VERSION ""

NS_ :

BS_:

BU_:

BO_ 2566786558 WSMSTR: 8 Vector__XXX
 SG_ NumberOfMembers : 0|8@1+ (1,0) [0|0] "" Vector__XXX

BO_ 2566838526 CA: 9 Vector__XXX
 SG_ ReservedBit : 48|1@1+ (1,0) [0|0] "" Vector__XXX
 SG_ AddressAssignment : 64|8@1+ (1,0) [0|255] "" Vector__XXX
 SG_ ArbitraryAddressCapable : 63|1@1+ (1,0) [0|1] "" Vector__XXX
 SG_ IndustryGroup M : 60|3@1+ (1,0) [0|7] "" Vector__XXX
 SG_ VehicleSystemInstance : 56|4@1+ (1,0) [0|15] "" Vector__XXX
 SG_ Function : 40|8@1+ (1,0) [0|255] "" Vector__XXX
 SG_ VehicleSystem m0 : 49|7@1+ (1,0) [0|127] "" Vector__XXX
 SG_ FunctionInstance : 35|5@1+ (1,0) [0|31] "" Vector__XXX
 SG_ ECUInstance : 32|3@1+ (1,0) [0|7] "" Vector__XXX
 SG_ ManufacturerCode : 21|11@1+ (1,0) [0|2047] "" Vector__XXX
 SG_ IdentityNumber : 0|21@1+ (1,0) [0|2097152] "" Vector__XXX
 SG_ VehicleSystem5 m5 : 49|7@1+ (1,0) [0|127] "" Vector__XXX
 SG_ VehicleSystem4 m4 : 49|7@1+ (1,0) [0|127] "" Vector__XXX
 SG_ VehicleSystem3 m3 : 49|7@1+ (1,0) [0|127] "" Vector__XXX
 SG_ VehicleSystem2 m2 : 49|7@1+ (1,0) [0|127] "" Vector__XXX
 SG_ VehicleSystem1 m1 : 49|7@1+ (1,0) [0|127] "" Vector__XXX

BO_ 2565799678 AC: 8 Vector__XXX
 SG_ ReservedBit : 48|1@1+ (1,0) [0|0] "" Vector__XXX
 SG_ ArbitraryAddressCapable : 63|1@1+ (1,0) [0|1] "" Vector__XXX
 SG_ IndustryGroup M : 60|3@1+ (1,0) [0|7] "" Vector__XXX
 SG_ VehicleSystemInstance : 56|4@1+ (1,0) [0|15] "" Vector__XXX
 SG_ Function : 40|8@1+ (1,0) [0|255] "" Vector__XXX
 SG_ FunctionInstance : 35|5@1+ (1,0) [0|31] "" Vector__XXX
 SG_ ECUInstance : 32|3@1+ (1,0) [0|7] "" Vector__XXX
 SG_ ManufacturerCode : 21|11@1+ (1,0) [0|2047] "" Vector__XXX
 SG_ IdentityNumber : 0|21@1+ (1,0) [0|2097152] "" Vector__XXX
 SG_ VehicleSystem m0 : 49|7@1+ (1,0) [0|127] "" Vector__XXX
 SG_ VehicleSystem5 m5 : 49|7@1+ (1,0) [0|127] "" Vector__XXX
 SG_ VehicleSystem4 m4 : 49|7@1+ (1,0) [0|127] "" Vector__XXX
 SG_ VehicleSystem3 m3 : 49|7@1+ (1,0) [0|127] "" Vector__XXX
 SG_ VehicleSystem2 m2 : 49|7@1+ (1,0) [0|127] "" Vector__XXX
 SG_ VehicleSystem1 m1 : 49|7@1+ (1,0) [0|127] "" Vector__XXX

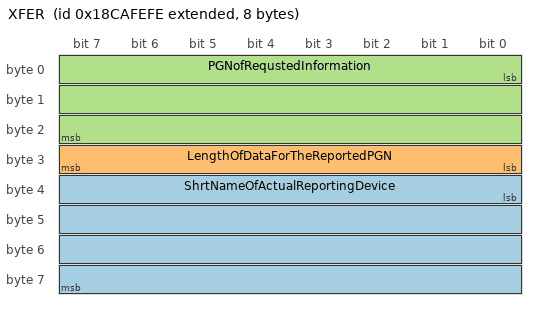
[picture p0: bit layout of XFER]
BO_ 2563440382 XFER: 8 Vector__XXX
 SG_ ShrtNameOfActualReportingDevice : 32|32@1+ (1,0) [0|0] "" Vector__XXX
 SG_ LengthOfDataForTheReportedPGN : 24|8@1+ (1,0) [0|255] "" Vector__XXX
 SG_ PGNofRequstedInformation : 0|24@1+ (1,0) [0|16777215] "" Vector__XXX

BO_ 2565603070 TPDT: 8 Vector__XXX
 SG_ SequenceNumber : 0|8@1+ (1,0) [0|255] "" Vector__XXX

BO_ 2565668606 TPCM: 8 Vector__XXX
 SG_ RoleOfSender m255 : 16|2@1+ (1,0) [0|0] "" Vector__XXX
 SG_ TotalNumberOfPacketsEoMA m19 : 24|8@1+ (1,0) [0|255] "" Vector__XXX
 SG_ TotalMessageSizeEoMA m19 : 8|16@1+ (1,0) [0|64255] "" Vector__XXX
 SG_ TotalMessageSizeBAM m32 : 8|16@1+ (1,0) [0|64255] "" Vector__XXX
 SG_ TotalNumberOfPacketsBAM m32 : 24|8@1+ (1,0) [0|255] "" Vector__XXX
 SG_ ConnectionAbortReason m255 : 8|8@1+ (1,0) [0|255] "" Vector__XXX
 SG_ NextPacketNumberToBeSent m17 : 16|8@1+ (1,0) [0|255] "" Vector__XXX
 SG_ NumberOfPacketsThatCanBeSent m17 : 8|8@1+ (1,0) [0|255] "" Vector__XXX
 SG_ PGNumber : 40|24@1+ (1,0) [0|16777200] "" Vector__XXX
 SG_ MaximumNumberOfPackets m16 : 32|8@1+ (1,0) [0|255] "" Vector__XXX
 SG_ TotalNumberOfPackets m16 : 24|8@1+ (1,0) [0|255] "" Vector__XXX
 SG_ TotalMessageSize m16 : 8|16@1+ (1,0) [0|64255] "" Vector__XXX
 SG_ ControlByte M : 0|8@1+ (1,0) [0|255] "" Vector__XXX

BO_ 2563374846 RQST2: 8 Vector__XXX
 SG_ ParameterGroupNumber : 0|24@1+ (1,0) [0|16777215] "" Vector__XXX
 SG_ UseTransferMode : 24|2@1+ (1,0) [0|3] "" Vector__XXX

BO_ 2565537534 RQST: 3 Vector__XXX
 SG_ ParameterGroupNumber : 0|24@1+ (1,0) [0|16777215] "" Vector__XXX

BO_ 2565406462 ACKM: 8 Vector__XXX
 SG_ AddressBusy m3 : 32|8@1+ (1,0) [0|255] "" Vector__XXX
 SG_ ControlByte M : 0|8@1+ (1,0) [0|255] "" Vector__XXX
 SG_ ParameterGroupNumber : 40|24@1+ (1,0) [0|16777215] "" Vector__XXX
 SG_ GroupFunctionValue : 8|8@1+ (1,0) [0|255] "" Vector__XXX
 SG_ AddressAccessDenied m2 : 32|8@1+ (1,0) [0|255] "" Vector__XXX
 SG_ AddressNegativeAcknowledgement m1 : 32|8@1+ (1,0) [0|255] "" Vector__XXX
 SG_ AddressAcknowledged m0 : 32|8@1+ (1,0) [0|255] "" Vector__XXX

CM_ BO_ 2566786558 "Working Set Master
This message is sent by the Master of a Working Set to identify how many members there are in said set.";
CM_ SG_ 2566786558 NumberOfMembers "The number of members in a particular Working Set.";
CM_ BO_ 2566838526 "Commanded Address
Message that is used to assign a source address to a specific Controller Application Name.";
CM_ SG_ 2566838526 AddressAssignment "This 8 bit field is the 9th byte of the data field of the Commanded Address message.  It contains the source address that is to be assigned to the CA that has the NAME corresponding to the one conveyed in the first eight bytes of this Commanded ...";
CM_ SG_ 2566838526 IndustryGroup "0 = Global; 
   1  = On-Highway; 
   2  = Agricultural and Forestry; 
   3  = Construction; 
   4  = Marine;
   5  = Industrial - Process
          Control - Stationary (Gen-Sets)
   6  = Reserve for SAE
   7  = Reserve for SAE";
CM_ SG_ 2566838526 ManufacturerCode "Assigned by NMEA 2000 Committee";
CM_ BO_ 2565799678 "Address Claimed
Message used to claim an address for a Controller Application.";
CM_ SG_ 2565799678 IndustryGroup "0 = Global; 
   1  = On-Highway; 
   2  = Agricultural and Forestry; 
   3  = Construction; 
   4  = Marine;
   5  = Industrial - Process
          Control - Stationary (Gen-Sets)
   6  = Reserve for SAE
   7  = Reserve for SAE";
CM_ SG_ 2565799678 ManufacturerCode "Assigned by NMEA 2000 Committee";
CM_ BO_ 2563440382 "Transfer
The Transfer PGN provides a mechanism for reporting multiple data sets for a given PGN.";
CM_ SG_ 2563440382 ShrtNameOfActualReportingDevice "Subset of the 64-bit NAME (SPN 2848), consisting of the most significant 32 bits, which identifies the controller application.  It excludes the manufacturer code and identity number.  It is sometimes used to identify a device for instance in the ...";
CM_ SG_ 2563440382 LengthOfDataForTheReportedPGN "Length of data reported with the associated PGN via the Transfer PGN.";
CM_ SG_ 2563440382 PGNofRequstedInformation "PGN associated with this transfer message";
CM_ BO_ 2565603070 "Transport Protocol - Data Transfer
Used for the transfer of data associated with Parameter Groups that have more than 8 bytes of data.";
CM_ SG_ 2565603070 SequenceNumber "Sequence Number (TP.DT)";
CM_ BO_ 2565668606 "Transport Protocol - Connection Mgmt
Used for the transfer of Parameter Groups that have 9 or more bytes of data.";
CM_ SG_ 2565668606 TotalNumberOfPacketsEoMA "Total number of packets received for RTS/CTS message. Zero not allowed.";
CM_ SG_ 2565668606 TotalMessageSizeEoMA "Total size (in bytes) of received message.";
CM_ SG_ 2565668606 TotalMessageSizeBAM "Total message size (in bytes). Messages shorter than 9 data bytes should be sent without utilizing the transport protocol. Messages longer than 1785 can not use the J1939 transport protocol.";
CM_ SG_ 2565668606 TotalNumberOfPacketsBAM "Total number of packets for BAM message. Zero not allowed.";
CM_ SG_ 2565668606 ConnectionAbortReason "Reason for connection abort message.
1 Already in one or more connection managed sessions and cannot support another.
2 System resources were needed for another task so this connection managed session was terminated.
3 A timeout occurred and this ...";
CM_ SG_ 2565668606 NextPacketNumberToBeSent "Next Packet Number to be sent (TP.CM_CTS). Zero not allowed.";
CM_ SG_ 2565668606 NumberOfPacketsThatCanBeSent "Number of Packets that can be sent (TP.CM_CTS)";
CM_ SG_ 2565668606 PGNumber "Requested PGN in the TP.CM_RTS message";
CM_ SG_ 2565668606 MaximumNumberOfPackets "Maximum number of packets for RTS/CTS message. Zero and one are not allowed.";
CM_ SG_ 2565668606 TotalNumberOfPackets "Total number of packets for RTS/CTS message. Zero not allowed.";
CM_ SG_ 2565668606 TotalMessageSize "Total message size. Messages shorter than 9 data bytes should be sent without utilizing the transport protocol. Messages longer than 1785 can not use the J1939 transport protocol.";
CM_ SG_ 2565668606 ControlByte "Control byte (I.e. Group Function) associated with the Transport Protocol - Connection Management (PGN 60,416)
16 (dec) - Request to Send
17 (dec) - Clear to Send
19 (dec) - End of Message ACK
32 (dec) - Broadcast Announce Message
255 (dec) - ...";
CM_ BO_ 2563374846 "Request 2
Used to Request a PGN from network device or devices and to specify whether the response should use the Transfer PGN or not. PGN and data set for all devices it is tasked with reporting.";
CM_ SG_ 2563374846 ParameterGroupNumber "PGN which is requested by Request2 message";
CM_ SG_ 2563374846 UseTransferMode "Requester is to respond the Request 2 message via the Transfer PGN

00 No
01 Yes
10 Undefined
11 NA";
CM_ BO_ 2565537534 "Request
This message type, identified by the PGN, provides the capability to request information globally or from a specific destination.";
CM_ SG_ 2565537534 ParameterGroupNumber "Whenever it is necessary to identify a Parameter Group in the data field of a CAN data frame, it will be expressed in 24 bits.  The Parameter Group Number is a 24 bit value that has the following constituent components:  Reserved bit, Data Page bit, ...";
CM_ BO_ 2565406462 "Acknowledgment Message
The Acknowledgment PG is used to provide a handshake mechanism between transmitting and receiving devices.";
CM_ SG_ 2565406462 ControlByte "Indicates the acknowledgement response.
0 - Positive Acknowledgment (ACK)
1 - Negative Acknowledgment (NACK)
2 - Access Denied (PGN supported but access denied)
3 - Cannot Respond (PGN supported but ECU cannot respond now) cannot respond with ...";
CM_ SG_ 2565406462 ParameterGroupNumber "PGN which is requested by the Request message";
CM_ SG_ 2565406462 GroupFunctionValue "Group Function of PGN being acknowledged. This field identifies for a device the specific group function of a PGN being acknowledged or declined.  This field is not used if the PGN being acknowledged or declined is not a group function PGN.";
BA_DEF_ SG_  "SigType" ENUM  "Default","Range","RangeSigned","ASCII","Discrete","Control","ReferencePGN","DTC","StringDelimiter","StringLength","StringLengthControl","MessageCounter","MessageChecksum","LowerPartOfSPN";
BA_DEF_ SG_  "GenSigStartValue" INT 0 2147483647;
BA_DEF_ SG_  "GenSigSendType" ENUM  "Cyclic","OnWrite","OnWriteWithRepetition","OnChange","OnChangeWithRepetition","IfActive","IfActiveWithRepetition","NoSigSendType";
BA_DEF_ SG_  "GenSigILSupport" ENUM  "No","Yes";
BA_DEF_ SG_  "SPN" INT 0 524287;
BA_DEF_ BO_  "J1939CPgSendTimeout" INT -1 3600000;
BA_DEF_ BO_  "J1939CPgTOS" INT 0 7;
BA_DEF_ BO_  "J1939PgAppearanceOnBus" ENUM  "Default","CAN_Extended","CANFD_Extended";
BA_DEF_ BO_  "GenMsgILSupport" ENUM  "No","Yes";
BA_DEF_ BO_  "GenMsgRequestable" INT 0 1;
BA_DEF_ BO_  "GenMsgSendType" ENUM  "cyclic","NotUsed","NotUsed","NotUsed","NotUsed","NotUsed","NotUsed","IfActive","noMsgSendType";
BA_DEF_ BO_  "VFrameFormat" ENUM  "StandardCAN","ExtendedCAN","reserved","J1939PG","reserved","reserved","reserved","reserved","reserved","reserved","reserved","reserved","reserved","reserved","StandardCAN_FD","ExtendedCAN_FD";
BA_DEF_ BO_  "SingleFrame" INT 0 1;
BA_DEF_DEF_  "SigType" "Default";
BA_DEF_DEF_  "GenSigStartValue" 0;
BA_DEF_DEF_  "GenSigSendType" "NoSigSendType";
BA_DEF_DEF_  "GenSigILSupport" "Yes";
BA_DEF_DEF_  "SPN" 0;
BA_DEF_DEF_  "J1939CPgSendTimeout" -1;
BA_DEF_DEF_  "J1939CPgTOS" 2;
BA_DEF_DEF_  "J1939PgAppearanceOnBus" "Default";
BA_DEF_DEF_  "GenMsgILSupport" "Yes";
BA_DEF_DEF_  "GenMsgRequestable" 1;
BA_DEF_DEF_  "GenMsgSendType" "noMsgSendType";
BA_DEF_DEF_  "VFrameFormat" "J1939PG";
BA_DEF_DEF_  "SingleFrame" 1;
BA_ "GenMsgRequestable" BO_ 2566838526 0;
BA_ "J1939PgAppearanceOnBus" BO_ 2565799678 1;
BA_ "GenMsgRequestable" BO_ 2565603070 0;
BA_ "GenMsgRequestable" BO_ 2565668606 0;
BA_ "GenMsgRequestable" BO_ 2563374846 0;
BA_ "GenMsgRequestable" BO_ 2565537534 0;
BA_ "GenMsgRequestable" BO_ 2565406462 0;
BA_ "SPN" SG_ 2566786558 NumberOfMembers 2409;
BA_ "SPN" SG_ 2566838526 AddressAssignment 2847;
BA_ "SPN" SG_ 2566838526 ArbitraryAddressCapable 2844;
BA_ "SPN" SG_ 2566838526 IndustryGroup 2846;
BA_ "SPN" SG_ 2566838526 VehicleSystemInstance 2843;
BA_ "SPN" SG_ 2566838526 Function 2841;
BA_ "SPN" SG_ 2566838526 FunctionInstance 2839;
BA_ "SPN" SG_ 2566838526 ECUInstance 2840;
BA_ "SPN" SG_ 2566838526 ManufacturerCode 2838;
BA_ "SigType" SG_ 2566838526 ManufacturerCode 1;
BA_ "SPN" SG_ 2566838526 IdentityNumber 2837;
BA_ "SPN" SG_ 2565799678 ArbitraryAddressCapable 2844;
BA_ "SPN" SG_ 2565799678 IndustryGroup 2846;
BA_ "SPN" SG_ 2565799678 VehicleSystemInstance 2843;
BA_ "SPN" SG_ 2565799678 Function 2841;
BA_ "SPN" SG_ 2565799678 FunctionInstance 2839;
BA_ "SPN" SG_ 2565799678 ECUInstance 2840;
BA_ "SPN" SG_ 2565799678 ManufacturerCode 2838;
BA_ "SigType" SG_ 2565799678 ManufacturerCode 1;
BA_ "SPN" SG_ 2565799678 IdentityNumber 2837;
BA_ "SPN" SG_ 2563440382 ShrtNameOfActualReportingDevice 2554;
BA_ "SigType" SG_ 2563440382 ShrtNameOfActualReportingDevice 4;
BA_ "SPN" SG_ 2563440382 LengthOfDataForTheReportedPGN 2553;
BA_ "SigType" SG_ 2563440382 LengthOfDataForTheReportedPGN 1;
BA_ "SPN" SG_ 2563440382 PGNofRequstedInformation 2552;
BA_ "SigType" SG_ 2563440382 PGNofRequstedInformation 6;
BA_ "SPN" SG_ 2565603070 SequenceNumber 2572;
BA_ "SPN" SG_ 2565668606 TotalNumberOfPacketsEoMA 2565;
BA_ "SPN" SG_ 2565668606 TotalMessageSizeEoMA 2564;
BA_ "SigType" SG_ 2565668606 TotalMessageSizeEoMA 1;
BA_ "SPN" SG_ 2565668606 TotalMessageSizeBAM 2567;
BA_ "SigType" SG_ 2565668606 TotalMessageSizeBAM 1;
BA_ "SPN" SG_ 2565668606 TotalNumberOfPacketsBAM 2568;
BA_ "SPN" SG_ 2565668606 ConnectionAbortReason 2570;
BA_ "SPN" SG_ 2565668606 NextPacketNumberToBeSent 2562;
BA_ "SPN" SG_ 2565668606 NumberOfPacketsThatCanBeSent 2561;
BA_ "SPN" SG_ 2565668606 PGNumber 2560;
BA_ "SigType" SG_ 2565668606 PGNumber 6;
BA_ "SPN" SG_ 2565668606 MaximumNumberOfPackets 2559;
BA_ "SPN" SG_ 2565668606 TotalNumberOfPackets 2558;
BA_ "SPN" SG_ 2565668606 TotalMessageSize 2557;
BA_ "SigType" SG_ 2565668606 TotalMessageSize 1;
BA_ "SPN" SG_ 2565668606 ControlByte 2556;
BA_ "SPN" SG_ 2563374846 ParameterGroupNumber 2574;
BA_ "SigType" SG_ 2563374846 ParameterGroupNumber 6;
BA_ "SPN" SG_ 2563374846 UseTransferMode 2575;
BA_ "SigType" SG_ 2563374846 UseTransferMode 4;
BA_ "SPN" SG_ 2565537534 ParameterGroupNumber 2540;
BA_ "SigType" SG_ 2565537534 ParameterGroupNumber 6;
BA_ "SPN" SG_ 2565406462 AddressBusy 3293;
BA_ "SPN" SG_ 2565406462 ControlByte 2541;
BA_ "SPN" SG_ 2565406462 ParameterGroupNumber 2547;
BA_ "SigType" SG_ 2565406462 ParameterGroupNumber 6;
BA_ "SigType" SG_ 2565406462 GroupFunctionValue 1;
BA_ "SPN" SG_ 2565406462 AddressAccessDenied 3292;
BA_ "SPN" SG_ 2565406462 AddressNegativeAcknowledgement 3291;
BA_ "SPN" SG_ 2565406462 AddressAcknowledged 3290;
VAL_ 2566838526 IndustryGroup 6 "Reserved for SAE" 7 "Reserved for SAE" 5 "IndustrialProcessCtrlStationary" 4 "Marine" 3 "Construction" 2 "Agricultural and Forestry" 1 "On-Highway" 0 "Global" ;
VAL_ 2566838526 Function 127 "Reserved" 126 "Reserved" 125 "Reserved" 124 "Reserved" 123 "Reserved" 122 "Reserved" 121 "Reserved" 120 "Reserved" 119 "Reserved" 118 "Reserved" 117 "Reserved" 116 "Reserved" 115 "Reserved" 114 "Reserved" 113 "Reserved" 112 "Reserved" 111 "Reserved" 110 "Reserved" 109 "Reserved" 108 "Reserved" 107 "Reserved" 106 "Reserved" 105 "Reserved" 104 "Reserved" 103 "Reserved" 102 "Reserved" 101 "Reserved" 42 "Water Pump Control" 41 "Lighting - Operator Controls" 40 "Seat Control" 39 "Ignition Control Module" 38 "Tire Pressure Control" 37 "Cab Controller" 36 "Pneumatic - System Controller" 35 "Suspension - System Controller" 34 "Hydraulic Pump Controller" 33 "System Monitor" 32 "Headway Controller" 31 "Propulsion Battery Charger" 30 "Management Computer" 29 "Virtual Terminal (in cab)" 28 "Off Vehicle Gateway" 27 "Power TakeOff (Secondary or Front)" 26 "Body Controller" 25 "Network Interconnect ECU" 24 "Vehicle Security" 23 "Vehicle Navigation" 22 "Aerodynamic Control" 21 "Cab Climate Control" 20 "Trip Recorder" 19 "Instrument Cluster" 18 "Suspension - Drive Axle" 17 "Suspension - Steer Axle" 16 "Steering Controller" 15 "Fuel System" 14 "Cruise Control" 13 "Retarder - Driveline" 12 "Retarder - Engine" 11 "Brakes - Drive Axle" 10 "Brakes - Steer Axle" 9 "Brakes - System Controller" 8 "Axle - Drive" 7 "Axle - Steering" 6 "Power TakeOff - (Main or Rear)" 5 "Shift Control/Console" 4 "Battery Pack Monitor" 3 "Transmission" 2 "Electric Propulsion Control" 1 "Auxiliary Power Unit (APU)" 0 "Engine" 100 "Reserved" 99 "Reserved" 98 "Reserved" 97 "Reserved" 96 "Reserved" 95 "Reserved" 94 "Auxiliary Display" 93 "Fuel Cell System" 92 "Current Sensor" 91 "Accessory Electric Motor Controller" 90 "Vehicle Adapter Communication Controller (VACC)" 89 "Supply Equipment Communication Controller (SECC)" 88 "Electric Power Converter" 87 "Driver Impairment Device" 86 "EV Communication Controller" 85 "Engine Injection Control Module" 84 "Start Aid Device" 83 "Printer" 82 "File Server" 81 "Hydraulic Powertrain" 80 "Electric Powertrain" 79 "Power Systems Manager" 78 "Fire Suppression System" 77 "Fuel Properties Sensor" 76 "Temperature Sensor" 75 "Supplemental Fan" 74 "Lubrication System" 73 "Rollover Detection Control" 72 "Coolant Valve Controller" 71 "Transfer Case Control" 70 "Auxiliary Regeneration Device" 69 "Engine Emission Aftertreatement System" 68 "Aftertreatment system gas measurement" 67 "Electrical System Controller" 66 "I/O Controller" 65 "Gas Flow Measurement" 64 "Endurance Braking" 63 "Engine Valve Controller" 62 "On-Board Diagnostic Unit" 61 "File Server/Printer" 60 "Cab Display" 59 "Starter" 58 "Fan Drive Control" 57 "Steering Column Unit" 56 "Communications Unit, Radio" 55 "Communications Unit, Satellite" 54 "Communications Unit, Cellular" 53 "Alternator/Charging System" 52 "Chassis Controller" 51 "Forward-Looking Collision Warning System" 50 "Auxiliary Heater" 49 "Clutch/Converter Control" 48 "Ramp Control" 47 "Information System Controller" 46 "Oil Sensor Unit" 45 "Vehicle Dynamic Stability Control" 44 "Exhaust Emission Control" 43 "Transmission Display" ;
VAL_ 2566838526 VehicleSystem 0 "Non-specific System" 127 "Not Available" ;
VAL_ 2566838526 ManufacturerCode 1410 "Allan Equipment Manufacturing Ltd." 1409 "Z Elektronika Kft." 1408 "Lenco Marine Inc." 1407 "Open-Agriculture" 1406 "Lumilex ALT SRL" 1405 "TELIG Electronics" 1404 "BRUSA HyPower AG" 1403 "Arco Marine" 1402 "ComNav Technology Ltd." 1401 "ROM Communications Inc." 1400 "IWN GmbH & Co. KG" 1399 "Hans Brantner & Sohn Fahrzeugbaugesellschaft mbH" 1398 "Gobius Sensor Technology AB" 1397 "SaMASZ Sp. Z o.o." 1396 "Fast Ag Solutions, LLC" 1395 "MLB Industrial" 1394 "Zhejiang Ruixing Electromechanical Technology Co., Ltd." 1393 "Powerland Technology Inc" 1392 "Phoenix America LLC" 1391 "AriensCo" 1390 "FJ Dynamics International Limited" 1389 "EVEX Co., LTD" 1388 "Nira Technology" 1387 "Radel (Pty) Ltd" 1386 "Smart Eye AB" 1385 "Pro Charging Systems, LLC" 1384 "Tecnoseal Foundry S.r.l." 1383 "Alpego S.p.A." 1382 "Thornwave Labs Inc." 1381 "Dr. Diesel Technologies" 1380 "ADVES GmbH & Co. KG" 1379 "Novag SAS" 1378 "Bertini SA" 1377 "ABD Solutions" 1376 "SUNS International, LLC" 1375 "ŠKODA ELECTRIC a.s." 1374 "CASAPPA S.p.A." 1373 "Centek Industries" 1372 "Elco Motor Yachts" 1371 "First Mode" 1370 "Emtech S.A." 1369 "Electric Yacht" 1368 "RAD Propulsion Ltd" 1367 "Dewulf NV" 1366 "Telemecanique Sensors & Switches" 1365 "JVCKENWOOD Corporation" 1364 "Yashu Systems" 1363 "Calix AB" 1362 "Zparq AB" 1361 "Nantong Saiyang Electronics Co., Ltd." 1360 "Lemca Vision" 1359 "BlueNav" 1358 "Fontaine Fifth Wheel" 1357 "TireCheck" 1863 "Thomas G. Faria Co." 1862 "Sanshin" 1861 "Vector North America (formerly Vector Cantech)" 1860 "MMP" 1859 "Kvaser AB" 1858 "Litton" 1857 "Simrad" 1856 "Trimble" 1855 "Furuno USA" 1854 "Northstar Technologies" 1853 "Japan Radio Co" 1852 "Navionics" 1851 "RayMarine" 1850 "Seastar Solutions (formerly Teleflex)" 1569 "621 Technologies Inc." 1551 "LMCE Group" 1550 "Mario Tanzi S.A." 1549 "AM Co., Ltd." 1546 "ESMART" 1545 "RoadEazy" 1544 "Geophysical Survey Systems, Inc." 1543 "GT Joysticks AG" 1542 "Global Digital Instruments" 1541 "Solid State Marine" 1540 "Ideas & Motion" 1539 "Ceday Information Technologies" 1538 "Quick S.p.A." 1537 "Anyload Weigh & Measure Inc." 1536 "Tatra Trucks a.s." 1535 "LOX Container Technology AB" 1534 "BluVein" 1533 "Rieker Inc." 1532 "E-Switch, Inc." 1531 "Kobelco Construction Machinery Co.,Ltd." 1530 "Roelama B.V." 1529 "Industrie Elektronik Brilon GmbH" 1528 "Savant Technology" 1527 "Richardt Steuer- und Regelgeraete GmbH" 1526 "MITSUBISHI MAHINDRA AGRICULTURAL MACHINERY CO.,LTD." 1525 "Emsiso-emDrive" 1524 "Ocean Infinity Solutions Limited" 1523 "Carlson Software" 1522 "American Thermal Instruments" 1521 "Agricolmeccanica" 1520 "SRT Marine Systems PLC" 1519 "Volboff Electron Science and Technology Co., Ltd." 1518 "Nova Kool Manufacturing ULC" 1517 "Daedong Corporation" 1516 "THERMIS spol. s r.o." 1515 "Ingeniería y Sistemas Cerea" 1514 "SYMX.ai" 1513 "Sy-Klone International" 1512 "Lumitec LLC" 1511 "APATOR METRA s.r.o." 1510 "Austin Motor Works" 1509 "Bondioli & Pavesi" 1508 "Xwatch Safety Solutions Ltd. part of Hexagon" 1507 "Apex.AI, Inc." 1506 "Expion360" 1505 "BC Motion" 1504 "Nimbus Power Systems, Inc." 1503 "Rosemount Specialty Products" 1502 "Barantech" 1501 "Reverso Pumps LLC" 1500 "Scanstrut Inc." 1499 "Hydrasystem SP. Z O.O." 1498 "PM Pfanzelt Maschinenbau GmbH" 1497 "ERMO Spa" 1496 "AgriRobot" 1495 "FlyAgData" 1494 "RAPITRONICS" 1493 "Jantop Oy" 1492 "Softivert" 1491 "Power Pollen" 1490 "Clean Republic SODO, LLC" 1489 "Lite-Check LLC" 1488 "Boetkin Technology Co., LTD" 1487 "Geosoft" 1486 "Xpanner" 1485 "Lester Electrical" 1484 "AgroOSA" 1483 "Nanjing Sandemarine Information Technology Co., Ltd." 1482 "CMC Marine" 1481 "E-Force Marine" 1480 "Thermo King" 1479 "A-Electronix" 1478 "Alps Alpine Co., Ltd." 1477 "TOBROCO-GIANT" 1476 "Wilhelm Stoll Maschinenfabrik GmbH" 1475 "DSP Solutions, Inc." 1474 "Calex Electronics Limited" 1473 "Cranesmart Systems, Inc." 1472 "Acculon Energy" 1471 "FT Technologies" 1470 "GemOne NV" 1469 "LS Mtron" 1468 "Senquip" 1467 "S.A.E.T. s.r.l." 1466 "Sveaverken Svea Agri AB" 1465 "Watteco" 1464 "Hi-Target Surveying Instrument Co., Ltd." 1463 "STOK Electric" 1462 "Trackunit ApS" 1461 "Vanquish Yachts" 1460 "Tocaro Blue" 1459 "Advanced Input Systems" 1458 "RideController LLC" 1457 "Albach Maschinenbau AG" 1456 "Krampe Fahrzeugbau GmbH" 1455 "Eberspächer Climate Control Systems International GmbH" 1454 "QTIS B.V." 1453 "Vital Battery" 1452 "Micro-Air LLC" 1451 "Guangdong ePropulsion Technology Ltd." 1450 "Agrivaux" 1449 "Bontaz Centre" 1448 "Elmer's Manufacturing" 1447 "Innotag Distributions Inc." 1446 "Roswell Marine" 1445 "Starboard Yacht Group" 1444 "Micropower Group" 1443 "SoilEssentials Limited" 1442 "EVYTRA GmbH" 1441 "Shanghai Allynav Technology Co.,Ltd." 1440 "Egis Mobile Electric" 1439 "PredictWind Ltd" 1438 "Aeolionics" 1437 "DOKEN Technology Co. Ltd." 1436 "M-extend" 1435 "Heilongjiang Huida Technology Co., Ltd" 1434 "eSurvey GNSS Ltd." 1433 "Unicontrol ApS" 1432 "MDH Defence Ltd." 1431 "Nauto Inc." 1430 "Mantracourt Electronics Ltd" 1429 "Nikola Corporation" 1428 "Samo Maschinenbau GmbH" 1427 "REITER RESPIRO" 1426 "Samson Group" 1425 "Electronics in Agriculture, School of Engineering, University of Galway" 1424 "Bewis" 1423 "AC S.A." 1422 "xTCU AG" 1421 "Clarios, LLC" 1420 "TALOS - Precision Measurement Technologies" 1419 "iPatch Marine" 1418 "Karluna Engineering" 1417 "Revatek LLC" 1416 "Wavetronix LLC" 1415 "Máquinas Agrícolas Jacto S.A." 1414 "INTRACOM DEFENSE S.A." 1413 "OHNOH2O LLC" 1412 "Naocontrol S.L." 1411 "Shanghai Huace Navigation Technology Ltd." 1356 "Nordic Lights Ltd" 1355 "DROP Agricultura Ltda" 1354 "Técnicas de Electrónica y Automatismos, S.A." 1353 "Ocean LED Marine Ltd" 1352 "NISHIYAMA Corporation" 1351 "Motorenfabrik Hatz GmbH & Co. KG" 1350 "AGRONETIC" 1349 "ANNABURGER Nutzfahrzeug GmbH" 1348 "Radian IoT, Inc." 1347 "Munckhof Fruit Tech Innovators" 1346 "Einboeck GmbH" 1345 "PRIGNITZ Mikrosystemtechnik GmbH" 1344 "Haulotte Group" 1343 "Heavy Data GmbH" 1342 "DKE-Data GmbH & Co. KG" 1341 "Ag Express Electronics" 1340 "ORELTEK Elektronik ve Yazilim Teknolojileri" 1339 "Tillett and Hague Technology Limited" 1338 "Volta Trucks AB" 1337 "Barnacle Systems Inc." 1336 "Aegis Power Systems, Inc." 1335 "CPDEVICE" 1334 "Greer Company" 1333 "xFarm Technologies SA" 1332 "Fairbanks Scales, Inc." 1331 "Dolphin Charger" 1330 "Warwick Control Technologies" 1329 "IDM S.r.l." 1328 "PerPlant ApS" 1327 "Frans Vervaet B.V." 1326 "HBC-radiomatic GmbH" 1325 "OPW (formerly BASE Engineering Inc.)" 1324 "Bourgault Industries" 1323 "Briter Products, Inc." 1322 "Movimatica" 1321 "PATLITE Corporation" 1320 "Triskel Marine Ltd" 1319 "I/O Controls Corporation" 1318 "Atlis Motor Vehicles" 1317 "GMM - Global Maritime Management GmbH" 1316 "Hinkley Yachts" 1315 "SMPC Technologies Ltd." 1314 "Newton Crouch Company, LLC" 1313 "United States Army - Ground Vehicle Systems Center" 1312 "Control Devices Pty Ltd" 1311 "Humphree AB" 1310 "LPL Systems (formerly Loughborough Projects Ltd)" 1309 "Shanghai Zhichuan Electronic Tech Co., Ltd." 1101 "DIS Sensors B.V." 1100 "LINK Marine Technologies (formerly Smart Yachts International Limited)" 1099 "MadgeTech, Inc" 1098 "Preh GmbH" 1097 "M2M Craft Co., Ltd" 1096 "Texense Sensors" 1095 "WEG Drives and Controls - Automação Ltda" 1094 "Tokushu Denki" 1093 "innolectric" 1092 "Scheiber" 1091 "Wheel Monitor Inc." 1090 "E-T-A Circuit Breakers Ltd" 1089 "Carrosserie HESS AG" 1088 "E-T-A Circuit Breakers" 1087 "ITPhotonics S.r.l." 1086 "Life Racing Ltd" 1085 "Wet Sounds, LLC" 1084 "Shadow-Caster LED lighting LLC" 1083 "Nauticoncept" 1082 "TÜMOSAN Engine and Tractor Co." 1081 "Imcon Electronics, s.r.o." 1080 "Epsilor-Electric Fuel Ltd." 1079 "Carl Zeiss Spectroscopy GmbH" 1078 "GE Appliances" 1077 "Ymer Technology" 1076 "DOGA S.A." 1075 "Uniden America Corporation" 1074 "Kindhelm / Navigs Oy" 1073 "Manitou Equipment America LLC" 1072 "La Marche Manufacturing Company" 1071 "MACH SYSTEMS s.r.o." 1070 "Quick-teck Electronics Ltd" 1069 "Lithionics Battery LLC" 1068 "Zapi S.p.A." 1067 "Tecomec S.r.l." 1066 "Spot Zero Water" 1065 "CALYPSO Instruments" 1064 "Omnitech Robotics Inc." 1063 "SolSteer" 1062 "Marol Co Ltd" 1061 "Volvo Construction Equipment" 1060 "Scale-Tec" 1059 "Boatrax" 1058 "Bondioli & Pavesi SpA" 1057 "EquipmentShare" 1056 "Lithium Pros" 1055 "EXA Computing GmbH" 1054 "Schmotzer Hacktechnik GmbH & Co. KG" 1053 "Vetus Maxwell, Inc." 1052 "Pfreundt" 1051 "ProNav AS" 1050 "Spacenus GmbH" 1049 "S&S Cycle" 1308 "Agtecnic" 1307 "Smart AG Systems" 1306 "Koden Electronics Co., Ltd." 1305 "dragonfly Energy" 1304 "Palfinger Europe GmbH" 1303 "Carbon Bee AgTech" 1302 "ProMariner" 1301 "Tecumseh do Brasil Ltda" 1300 "Watt Fuel Cell Corporation" 1299 "Energy Solutions" 1298 "SFOGGIA Agriculture Division S.r.l." 1297 "Micro-Epsilon Messtechnik GmbH & Co. KG" 1296 "Hexagon" 1295 "SIP d.d." 1294 "TR-Electronic GmbH" 1293 "POSITAL" 1292 "SUMITOMO CONSTRUCTION MACHINERY CO., LTD." 1291 "Forward Thinking Systems LLC" 1290 "WaveTamer Partners LLC" 1289 "Loadrite (Auckland) Ltd." 1288 "ANELLO Photonics" 1287 "Spartan Radar" 1286 "NEXAT GmbH" 1285 "Graco Inc." 1284 "Robot Makers GmbH" 1283 "LTG Tech" 1282 "COTEK ELECTRONIC IND. CO., LTD" 1281 "iQuus" 1280 "SANTEST CO., LTD." 1279 "Ognibene Power S.p.A." 1278 "Comrod Communication Group" 1277 "BMZ Germany GmbH" 1276 "Aspin Kemp & Associates" 1275 "O.M.P. Officine Mazzocco Pagnoni S.r.l." 1274 "LDL Technology" 1273 "Clearflame Engines Inc" 1272 "Samsara Inc." 1271 "Raven Connected" 1270 "Versalift Denmark A/S" 1269 "VIS Hydraulics s.r.l." 1268 "Back 40 Precision Inc." 1267 "Wacker Neuson SE" 1266 "Hyundai Doosan Infracore" 1265 "IPETRONIK GmbH & Co KG" 1264 "Microelect" 1263 "BOS Balance of Storage Systems AG" 1262 "Fort Robotics" 1261 "AgXeed" 1260 "Interactive Technologies, Inc." 1259 "Grayson Automotive Services Limited" 1258 "AGC Technologies" 1257 "KOSTAL" 1256 "Dimensions Agri Technologies AS" 1255 "Altec Industries, Inc." 1254 "ARADEX AG" 1253 "Trafag AG" 1252 "APV - Technische Produkte GmbH" 1251 "Valmet Automotive EV Power Ltd" 1250 "ELHO" 1249 "Integrated Power Solutions AG" 1248 "O.M.F.B. S.p.A. Hydraulic Components" 1247 "GRIFA" 1246 "Rother Industries & Technology" 1245 "Raritan Engineering Company, Inc" 1244 "Planti Center" 1243 "AvMap S.r.l." 1242 "Super Start Batteries" 1241 "Ineo Systrans" 1240 "TiMOTION" 1239 "SuperTrack Aps" 1238 "Honda Electronics Co., Ltd" 1237 "Changzhou Lambda Electronic Co., Ltd" 1236 "Agrosystem" 1235 "NESAN Automotive Inc." 1234 "American Battery Solutions" 1233 "nke Marine Electronics" 1232 "Treffler Maschinenbau GmbH & Co. KG" 1231 "Excidor AB" 1230 "Nick Abbey Digital Agriculture Ltd" 1229 "Arcon Designs, LLC" 1228 "INTILION GmbH" 1227 "YAHATA Co., Ltd." 1226 "Piippo Hydraulic" 1225 "SeedMaster Manufacturing Ltd" 1224 "Neuser Elektrotechnik GmbH" 1223 "Toyo Agricultural Machinery Manufacturing Co., Ltd" 1222 "Tough Tech Ltd." 1221 "Norcold Inc." 1220 "Catamaran Electronics LLC" 1219 "Weidmueller Interface GmbH & Co. KG" 1218 "Septentrio" 1217 "FSG Fernsteuergeräte Kurt Oelsch GmbH" 1216 "SMP Poland sp. z o.o." 1215 "Power Control Systems" 1214 "Element 1" 1213 "Apollo Tyres Ltd" 1212 "TAO Performance" 1211 "Kiwon Electronics Co., Ltd." 1210 "Ambra Solutions" 1209 "Bauser GmbH & Co. KG" 1208 "Afflield Kft. (MachineryGuide)" 1207 "UEC Electronics" 1206 "STE Solutions B.V." 1205 "Carbon Autonomous Robotic Systems" 1204 "Miller Technology Incorporated" 1203 "Equipment Technologies, Inc." 1202 "OSCAR ELECTRONICS SRL (formerly OSCAR Elettronica)" 1201 "Emisense Technologies, LLC" 1200 "Xinuo Information Technology (Xiamen) Corporation Limited" 1199 "ELEO Technologies B.V." 1198 "ComLink Equipamentos Eletrônicos Ltda" 1197 "SOLGE Corporation" 1196 "Terra Care GmbH" 1195 "düvelsdorf" 1194 "Sierra Marine" 1193 "emotas embedded communication GmbH" 1192 "Airmoniq Pro Kft." 1191 "Pacoma USA, Inc." 1190 "Sirros IoT" 1189 "Autotrasporti Cavallo G&V" 1188 "G-SNS" 1187 "TiTAN-Project LLC" 1186 "Sailmon BV" 1185 "WFCO Electronics" 1184 "AMA S.p.A." 1183 "Zipwake AB" 1182 "Rottmann Automation" 1181 "Banjo Corporation" 1180 "Murata Power Solutions Inc." 1179 "QS Control srl" 1178 "ERO GmbH" 1177 "RNG International Inc." 1176 "Asuns Corp." 1175 "MAGTEC Products, Inc." 1174 "Agricon GmbH" 1173 "philippi elektrische systeme gmbh" 1172 "Hyzon Motors" 1171 "Vista Manufacturing" 1170 "Poseidon Ocean Systems Ltd." 1169 "Sea Machine Robotics Inc." 1168 "Masats S.A." 1167 "Tevva Motors" 1166 "Wachendorff Automation GmbH & Co. KG" 1165 "InnoTotal AB" 1164 "SEG Automotive" 1163 "DFX Technologies LLC" 1162 "PEL-tuote Oy" 1161 "Griessbach GmbH" 1160 "MG Energy Systems B.V." 1159 "Bel Power Solutions" 1158 "Technoton Electronics" 1157 "Carriergistics" 1156 "Nokian Tyres" 1155 "LACOS GmbH (formerly LACOS Computerservice GmbH)" 1154 "TBS Electronics BV" 1153 "Kawasaki Heavy Industries, Ltd." 1152 "Vredo Dodewaard B.V." 1151 "Orca Technologies AS" 1150 "BSB Artificial Intelligence GmbH" 1149 "Wuxi Shengbang Electronics Co., Ltd" 1148 "Stercom Power Solutions GmbH" 1147 "Dana Inc." 1146 "Rometron" 1145 "Kiwi Yachting" 1144 "Troo Corporation" 1143 "Elektro-Szoft 2000" 1142 "Truma" 1141 "MRS Electronic GmbH & Co. KG" 1140 "Across Oceans Systems Ltd." 1139 "ASP Technology" 1138 "Micro-Sensor GmbH" 1137 "SIKO GmbH" 1136 "Primosensor GmbH" 1135 "Japan Aviation Electronics Industry, Limited" 1134 "Master Schools at Ostbahnhof" 1133 "MEGATRON Elektronik GmbH & Co. KG" 1132 "Tokachi Zaidan" 1131 "Guliwer electronics s.r.o." 1130 "Vitesco Technologies" 1129 "Spectrolytic GmbH" 1128 "Citoon Electronic Technology (Tianjin) Co., Ltd." 1127 "ElectroMaax" 1126 "Auralix" 1125 "Griffith-Elder & Co. Ltd." 1124 "Fortron Agriculture" 1123 "QP Hydraulics" 1122 "GT Inc." 1121 "Platform Science" 1120 "Elettromedia s.r.l." 1119 "Balmar LLC" 1118 "L3Harris ASV" 1117 "LG Chem, Ltd" 1116 "HR Agrartechnik GmbH" 1115 "Gems Sensors & Controls" 1114 "Bob's Machine" 1113 "iVolve Pty Ltd" 1112 "Bollinger Motors" 1111 "SEPPI M." 1110 "Analytic Systems Ware (1993) Ltd." 1109 "Dockmate" 1108 "ORBCOMM" 1107 "Dräger Safety" 1106 "Great Dane LLC" 1105 "Redekop Manufacturing" 1104 "The Toro Company" 1103 "Diesel Laptops" 1102 "Carl Geringhoff GmbH & Co. KG" 1048 "Agrivation UG" 1047 "Sonic Corporation" 1046 "Praxidyn" 1045 "CMR Group" 1044 "Xee" 1043 "Hyva" 1042 "engcon group" 1041 "EZ Lynk" 1040 "BPE Electronics Srl" 1039 "Liugong Dressta Machinery" 1038 "EMIT Technologies, Inc." 1037 "Dragonfly Energy Corp." 1036 "Bender GmbH & Co. KG" 1035 "Agres" 1034 "Siren Marine" 1033 "ECCO Safety Group" 1032 "SIMOL S.p.A." 1031 "Flintec UK Ltd." 1030 "Tume-Agri Oy" 1029 "The Marine Guardian LLC" 1028 "Autel Intelligent Technology Corp., Ltd" 1027 "Goldacres PTY LTD" 1026 "ZTR Control Systems, LLC" 1025 "eze System, Inc." 1024 "Inventus Power" 1023 "PEAK-System Technik GmbH" 1022 "ITC Inc" 1021 "Entratech Systems LLC" 1020 "Team Italia Marine srl (formerly Onyx Marine Automation s.r.l.)" 1019 "Codek Foundries" 1018 "Flex TTS" 1017 "Caldaro AB" 1016 "Röhren- und Pumpenwerk BAUER GmbH" 1015 "SECURITAG SAS" 1014 "Briri Maschinenbau GmbH" 1013 "Allochis E-Tec" 1012 "Rhodan Marine Systems of Florida LLC" 1011 "Soundmax Electronics Ltd" 1010 "Agricultural Industry Electronics Foundation e.V." 1009 "TouchTronics, Inc." 1008 "Lintest Systems LLC" 1007 "Maschinenfabrik Meyer-Lohne GmbH" 1006 "Proterra" 1005 "TSE Brakes, Inc." 1004 "Ultraflex SpA" 1003 "technotrans SE" 1002 "Kussmaul Electronics Co." 1001 "Cleral Inc." 1000 "Landmaschinen Wienhoff GmbH" 999 "TerraTroniq B.V." 998 "Transcell Technology Inc" 997 "Xenta Systems Srl" 996 "Eniquest Pty Ltd" 995 "Circuitlink Pty Ltd." 994 "Morris Industries Ltd." 993 "Alelion Energy Systems AB" 992 "MarineIOT LLC" 991 "Deutronic Elektronik GmbH" 990 "SAMSUNG SDI Co., Ltd." 989 "Flux-Geräte GmbH" 988 "Voith Turbo" 987 "Baltic Car Equipment" 986 "AAMP Global" 985 "NLR, LLC" 984 "E-T-A Elektrotechnische Apparate GmbH" 983 "Dezwaef NV" 982 "Briggs & Stratton Corporation" 981 "Kobelt Manufacturing Co. Ltd" 980 "Gussi Italia S.R.L." 979 "McHale" 978 "Canfield Connector" 977 "Copeland LP (formerly Emerson Electric Co.)" 976 "Derive Systems, Inc." 975 "Siemens AG" 974 "Pico Technology Limited" 973 "Zasso GmbH" 972 "Axion AG" 971 "B+B Smartworx" 970 "Jaboni Power Products, LLC" 969 "Blue Sea Systems" 968 "Cox Powertrain Limited" 967 "Moteck Electric Corp." 966 "VisibleFarm" 965 "Ro-Sys Software" 964 "AgroVIR Kft" 963 "Thomason Jones Company, LLC" 962 "Timbolier Industries, Inc." 961 "POK SAS" 960 "Vemcon GmbH" 959 "Cascade Corporation" 958 "NHK MEC Corporation" 957 "Sierra Wireless Inc" 956 "Piher Sensors & Controls S.A." 955 "Hottinger Baldwin (Suzhou) Electronic Measurement Technology Co., Ltd." 954 "Setec Pty Ltd" 953 "Curtiss-Wright" 952 "Tan Delta Systems Ltd" 951 "Exor International S.p.A." 950 "RE:Lab s.r.l." 949 "ŠKODA ELECTRIC a.s." 948 "Donix" 947 "Gerd Bär GmbH" 946 "Hydac Tecnologia Ltda" 945 "Equalizer AG" 944 "ZONTISA Marine SL" 943 "FISCHER AG Präzisionspindeln" 942 "Vogelsang GmbH & Co. KG" 941 "Navya" 940 "Dometal Oy" 939 "Warn Industries, Inc." 938 "LEVEL Systems" 937 "Precision Circuits Inc" 936 "Hi-tech Millennium" 935 "Meels GmbH & Co. KG" 934 "Farmobile, Inc." 933 "Delta Mobile Systems, Inc." 932 "Discover Battery" 931 "Enertec Marine Ltd" 930 "Ecotronix Corp." 929 "Jl Marine Systems, Inc." 928 "EAO Automotive GmbH & Co. KG" 927 "Saicon" 926 "Buhler Industries Inc." 925 "GW Lisk Company" 924 "PAS Peschak Autonome Systeme GmbH" 923 "ELTEK S.p.A." 922 "Terberg Benschop B.V." 921 "ROPA Fahrzeug- und Maschinenbau GmbH" 920 "MTD Consumer Group Inc." 919 "Furrion LLC" 918 "AMW Machine Control, Inc" 917 "Sentinel d.o.o." 916 "Hans Turck GmbH & Co. KG (formerly Turck Inc.)" 915 "Dosificacion y sistemas electronicos S.L. (DSE)" 914 "ZETOR TRACTORS a.s." 913 "Toyota Motor Corporation" 912 "Steyr Motors GmbH" 911 "Nautic-On" 910 "Hermann Paus Maschinenfabrik GmbH" 909 "Marines Co., Ltd." 908 "Chonbuk National University Department of Electronics" 907 "strautmann" 906 "MOBA AG" 905 "ASA Electronics" 904 "Equipment Safety Systems Pty. Ltd. (EQSS)" 903 "InMotion" 902 "Bucher Hydraulics" 901 "Zivan Srl" 900 "OSB connagtive GmbH (formerly OSB AG)" 899 "Lippert Components, Inc" 898 "Josef Kotte Landtechnik GmbH & Co. KG" 897 "Dot Technology Corp." 896 "NextFour Solutions Ltd" 895 "Peloton Technology" 894 "Rhodan Marine Systems of Florida LLC (Duplicate entry; use MFR ID 1012)" 893 "KlinkTechnics Ltd." 892 "Mectronx Corp" 891 "CarrierWeb" 890 "L3 Technologies, Inc." 889 "SANY America Inc" 888 "Carma Systems Inc" 887 "Turntide Transport Limited (formerly Hyperdrive Innovation Limited)" 886 "Hitachi Zosen Corporation" 885 "SICK AG (formerly SICK Stegmann GmbH)" 884 "Sure Grip Controls Inc." 883 "Swift Navigation, Inc." 882 "BHTronik GmbH & Co. KG" 881 "Sovema" 880 "Revision Military" 879 "PG Trionic, Inc." 878 "FOTON" 877 "SICK ATech GmbH" 876 "SUCO Robert Scheuffele GmbH & Co. KG" 875 "Salvarani S.r.l." 874 "MTA S.p.A." 873 "Garnet Instruments Ltd." 872 "Kählig Antriebstechnik GmbH" 871 "Agri-Fab (formerly Superior Tech Inc)" 870 "Textron Fleet Management" 869 "Intercomp" 868 "Data Panel Corp" 867 "Skeleton Technologies" 866 "Netradyne, Inc." 865 "MyEasyFarm" 864 "Streamline Transportation Technologies Inc." 863 "SMAG" 862 "Prospec Electronics" 861 "Adel System S.r.l." 860 "Michelin" 859 "Valor" 858 "Littelfuse" 857 "Zoomlion Heavy Industry NA, Inc" 856 "FarmFacts GmbH" 855 "Toshiba Infrastructure Systems & Solutions Corporation" 854 "GEMAC Chemnitz GmbH" 853 "Teledyne RESON B.V." 852 "Velvac Inc" 851 "Novotechnik Messwertaufnehmer OHG" 850 "Geoprospectors GmbH" 849 "MTS Maschinentechnik Schrode AG" 848 "ningupex" 847 "Oceanvolt" 846 "L3 Magnet-Motor" 845 "GMB Güstrower Maschinenbau GmbH" 844 "FELL AS" 843 "Hendrickson Truck Commercial Vehicle Systems" 842 "DigiDevice Srl" 841 "Agra-GPS" 840 "E.S.T.E. Srl" 839 "Indexator Rotator Systems AB" 838 "Teamsurv Ltd" 837 "Famic Technologies Inc." 836 "Signature4" 835 "PetTrack Ltd." 834 "Pioneer Microsystems, Inc." 833 "Electrum Automation AB" 832 "Heizomat Gerätebau-Energiesysteme GmbH" 831 "DOK-ING Ltd." 830 "Ultra Motion LLC" 829 "Drov Technologies, Inc." 828 "AgriBrink Inc." 827 "INmatix Technology Group Ltd" 826 "Lewmar Marine Inc" 825 "BPW Hungária" 824 "Undheim Systems AS" 823 "ACEINNA, Inc (formerly MEMSIC, Inc)" 822 "Bren-Tronics, Inc." 821 "Thorsen Teknik A/S" 820 "DIaLOGIKa Gesellschaft fuer angewandte Informatik mbH" 819 "Preco Electronics" 818 "HGNSS" 817 "TE Connectivity Sensor Solutions" 816 "UniStrong" 815 "FLIR Systems, Inc." 814 "Kronotech Srl (formerly Soltec Soluzioni Tecnologiche Srl)" 813 "Thales Suisse SA" 812 "Torch Technologies" 811 "Blue Water Desalination" 810 "Dutch Power Company" 809 "HMS Industrial Networks AB" 808 "RIMEX Supply Ltd." 807 "Schneider-Electric" 806 "Charge Automotive Ltd" 805 "Gundersen & Løken AS" 804 "ASA Electronics" 803 "Gill Sensors & Controls Limited" 802 "SPBI (Bj Technologie)" 801 "LOR Manufacturing Company Inc." 800 "Delta-Q Technologies" 799 "Stillwater Designs and Audio, Inc. - KICKER" 798 "Lumishore Ltd" 797 "Tides Marine" 796 "Canadian Automotive Industries Ltd" 795 "Broyda Enterprises Pty Ltd" 794 "Shihlin Electric & Engineering Corporation" 793 "James Fisher Prolec" 644 "KUS USA" 643 "Bogballe A/S" 642 "Moog / Aspen Motion Technologies" 641 "Diverse Yacht Services" 640 "Power Solutions International" 639 "Startec s.r.l." 638 "KVH Industries, Inc." 637 "Bavaria Yachtbau GmbH" 636 "Divelbiss Corporation" 635 "Argo Tractors S.p.A." 634 "Rocky Research" 633 "TORC Robotics" 632 "Pepperl+Fuchs GmbH" 631 "Reltima" 630 "SmartDrive Systems Inc." 629 "Agri Info Design, Ltd." 628 "Falck Schmidt Defence Systems" 627 "Radio Ocean" 626 "AVL DiTEST GmbH" 625 "Global MRV Inc." 624 "Blackbox Machine Control Pty Ltd" 623 "Xirgo Technologies" 622 "Floyd Bell Inc" 621 "Hagie Manufacturing Company" 620 "BorgWarner Inc. (formerly Sevcon Ltd.)" 619 "Right Weigh Load Scales" 618 "Evrard SA" 617 "Zero Emission Vehicles" 616 "SMART-TEC s.r.o." 615 "Networkfleet, Verizon Telematics" 614 "ARLT Technologies GmbH" 613 "HKS Co., Ltd." 612 "Samwon IT" 611 "Esterline" 610 "Trail Tech" 609 "Walvoil S.p.A." 608 "Gale Banks Engineering" 607 "Knappco/Civacon" 606 "Intellian Technologies" 605 "Aventics GmbH" 604 "Rototilt Group AB (formerly Indexator Rototilt Systems AB)" 603 "Kereval" 602 "Nomad Digital Ltd." 601 "Navitas Systems" 600 "Aquatic AV" 599 "Spudnik Equipment Co, LLC" 598 "ABB Turbo Systems Ltd" 597 "Hydac Filter Systems GmbH" 596 "Brunelco Electronic Innovators B.V." 595 "CustomWare" 594 "Kongsberg Automotive" 593 "Sensata Technologies" 792 "Kostal Mexicana" 791 "AUTEC" 790 "VACALL" 789 "GRADALL" 788 "MoTeC Pty Ltd" 787 "Abertax Technologies Limited" 786 "Johnson Matthey Battery Systems" 785 "Fischer Panda GmbH" 784 "CM Automotive Systems, Inc." 783 "Loup Electronics Inc." 782 "AVR nv" 781 "Poly-Planar LLC" 780 "Turntide Transport Limited (formerly AVID Technology Ltd)" 779 "RLC Electronic Systems" 778 "Seakeeper Inc." 777 "Ocean Signal Ltd" 776 "HMI Systems LLC" 775 "ZIEHL-ABEGG Automotive GmbH" 774 "Taisho Corporation" 773 "Clarion Corporation of America" 772 "Blink Marine" 771 "Shaw Development, LLC" 770 "MONOSEM" 769 "Trombetta" 768 "Flores Automation, LLC" 767 "Alliance Wireless Technologies Inc." 766 "Epec Oy" 765 "GIGAVAC" 764 "Bednar FMT s.r.o." 763 "AT-Systems BVBA" 762 "ROJ s.r.l." 761 "MITA OLEODINAMICA S.p.A." 760 "Bernecker + Rainer Industrie Elektronik GmbH" 759 "Hydro-Gear" 758 "Banner Engineering Corp." 757 "IMPCO Technologies" 756 "Maschio Gaspardo S.P.A." 755 "Firefly Integrations" 754 "Parker Hannifin Corp., Automation Group" 753 "AIROD Technologies" 752 "Deep Sea Electronics Plc" 751 "Pacific Track" 750 "Joskin SA" 749 "Chart Inc." 748 "IFRA SRL - ISOTTA" 747 "Agratronix" 746 "SurePoint Ag Systems (formerly SureFire Ag Systems, Inc.)" 745 "Cidra Corporate Services Inc." 744 "Woosung Engineering Co., Ltd." 743 "Daemyung Elevator Co., Ltd." 742 "EROAD" 741 "Littelfuse, Inc (formerly Carling Technologies)" 740 "e-Traction" 739 "LXNAV d.o.o." 738 "Blue Ink Technologies" 737 "Balluff GmbH" 736 "Terex Aerial Work Platforms - Genie" 735 "AEM Performance Electronics" 734 "REAPsystems" 733 "Geotab Inc. (formerly Intendia S.L.)" 732 "Gefran S.p.A." 731 "Modine Manufacturing Company" 730 "BERTHOUD AGRICOLE" 729 "Liebherr" 728 "Streumaster (formerly Streumaster / Panien)" 727 "Dhoot Transmission Pvt Ltd." 726 "MIDORI PRECISIONS" 725 "Hitachi Construction Machinery Co., Ltd." 724 "Electronic Applications, Inc." 723 "Jabil Inc." 722 "Contelec AG" 721 "Hypro" 720 "WITZ Corporation" 719 "Cojali S. L." 718 "Micronet Inc" 717 "Yacht Devices Ltd" 716 "Eaton Control & Power Conversion Division (CPCD)" 715 "Autonnic Research Ltd" 714 "Kobashi Kogyo Co., Ltd." 713 "US Hybrid Corporation" 712 "LOR Manufacturing Company Inc." 711 "DAS Co., LTD" 710 "Greentronics Ltd." 709 "Marquardt GmbH" 708 "Lars Thrane A/S" 707 "Rochester Gauges Inc" 706 "Shanghai Diesel Engine Corporation Limited" 705 "SVAB Hydraulik AB" 704 "JL Audio, Inc." 703 "Hydro Tab Marine Engineering" 702 "Weichai Power Co., Ltd." 701 "BigRoad Inc." 700 "K-Tec Earthmovers Inc." 699 "Harman International (formerly Harman International Industries)" 698 "Scorpion Technologies Ltd." 697 "Ålö AB" 696 "DRS Network & Imaging Systems, LLC (DRS Technologies)" 695 "Weldon Technologies" 694 "GasTOPS Ltd." 693 "Agility Fuel Solutions (formerly Agility Fuel Systems)" 692 "Tanhay Corporation" 691 "Digitroll Agricultural Electronics" 690 "LINAK A/S" 689 "Aarcomm Systems Inc" 688 "Rockford Corp" 687 "Flight Systems, Inc." 686 "Taigene Electric Machinery Corp." 685 "ANEDO (formerly ANEDO Ltd.)" 684 "KEB" 683 "Fosen Elektro" 682 "Eckelmann AG" 681 "BEDIA Motorentechnik GmbH & Co. KG" 680 "AMVAC Chemical Corporation" 679 "OXE Marine AB (formerly Cimco Marine AB)" 678 "Motive Technologies, Inc. (formerly KeepTruckin, Inc.)" 677 "DSA Daten- und Systemtechnik GmbH" 676 "Danfoss IXA A/S" 675 "Kawasaki Motors, Ltd. (formerly Kawasaki Motors Corp., USA)" 674 "Yara International ASA" 673 "Caruelle Nicolas" 672 "OPTIMA Concept" 671 "Innovative Controls Inc." 670 "STEMCO LP" 669 "Quantum Fuel Systems Technologies Worldwide, Inc" 668 "MacDon Industries Ltd." 667 "Bartec" 666 "Schaeffler Technologies AG & Co., KG" 665 "Gebr. Bode GmbH & Co. KG" 664 "Level Developments Ltd" 663 "Delta Systems, Inc" 662 "Kissling Elektrotechnik GmbH" 661 "SPAL Automotive S.r.l." 660 "Auto-Gaz Centrum" 659 "Data Panel Corp." 658 "Shenzhen Jiuzhou Himunication Technology Co., Ltd" 657 "Terzo Power Systems" 656 "PRO SOLUS do Brasil" 655 "Genge & Thoma AG" 654 "Kohler Power Systems, Detroit Engine Development Center (DEDC)" 653 "AEV, spol. s r. o." 652 "MicroControl GmbH & Co. KG" 651 "Takakita Co, Ltd." 650 "Seiko Epson Corp." 649 "Control-Q B.V." 648 "OJSC Ekran" 647 "Siloking" 646 "Veenhuis Machines B.V." 645 "esd electronic system design gmbh" 592 "tecsis GmbH" 591 "United States Coast Guard" 590 "ARGO-HYTOS GMBH" 589 "MICO, Inc." 588 "Vignal Systems" 587 "JCA Electronics" 586 "Suzuki Motor Corp" 585 "Industrial Electronic Controls" 584 "CarMedialab GmbH" 583 "Yachtcontrol" 582 "Innovative Software Engineering" 581 "Väderstad AB (formerly Väderstad - Verken AB)" 580 "San Jose Technology, Inc." 579 "KVH Industries, Inc." 578 "advanSea" 577 "Denchi Power Ltd  (formerly ABSL Power Solutions Limited)" 576 "Vectia" 575 "Lytx" 574 "Vishay Precision Group" 573 "Orolia Ltd" 572 "Fasse Valves" 571 "Marinecraft Co., Ltd." 570 "frenzel + berg electronic GmbH & Co. KG" 569 "LORD MicroStrain Sensing Systems" 568 "Makersan Ltd. Co." 567 "Lithiumstart LLC" 566 "Geode Technology, Inc." 565 "Micro-Trak Systems, Inc." 564 "Auto Power Electronic" 563 "LOHR Sistemas Eletronicos LTDA" 562 "Bombardier Transportation GmbH" 561 "b-plus GmbH" 560 "Iowa State University, Agricultural and Biosystems Engineering" 559 "Four Peaks Navigation" 558 "Davis Instruments Corp." 557 "Rockson Automation GmbH" 556 "HD Hyundai Infracore Norway (formerly Doosan Infracore Norway)" 555 "Sasaki Corporation" 554 "iris-GmbH infrared & intelligent sensors" 553 "KIB Electronics" 552 "Matsuyama Plow Mfg Co, Ltd" 551 "Wexler CSD Ltd." 550 "SUN-A Corporation" 549 "ROAD Deutschland GmbH" 548 "TM4 Inc." 547 "Thomson Linear LLC" 546 "Maruyama Mfg Co, Inc." 545 "GS Global Resources (formerly GS Hydraulics)" 544 "Au Group Electronics" 543 "BAUER Maschinen GmbH" 542 "Dinamica Generale s.p.a." 541 "Total Fire Systems, Inc." 540 "Dinex A/S" 539 "Mobileview" 538 "Crop Ventures, Inc." 537 "Schrader Electronics Ltd." 536 "SSI Technologies" 535 "MOTORPAL, a.s." 534 "Webasto Thermo & Comfort SE" 533 "Doran Manufacturing, LLC" 532 "Onwa Marine Electronics Co Ltd." 531 "Genge & Thoma AG" 530 "NMEA" 529 "National Instruments Korea" 528 "Hoganas AB, Electric Drive Systems" 527 "GKN Walterscheid GmbH" 526 "LOFA Industries, Inc" 525 "Rust Sales INC" 524 "Vomax Instrumentation Pty. Ltd." 523 "Reggio Emilia Innovazione" 522 "Nebraska Tractor Test Laboratory" 521 "Clever Devices Ltd." 520 "Trapeze" 519 "Peeters Landbouwmachines b.v." 518 "Transas USA Inc." 517 "Noland Engineering" 516 "AVAT Automation GmbH" 515 "GINAF Trucks Nederland B.V." 514 "DISTek Integration, Inc." 513 "Precision Technology" 512 "Inpower LLC" 511 "SKY Agriculture (formerly Burel Production, formerly Sulky)" 510 "Marinesoft Co. Ltd" 509 "MOTORTECH GmbH" 508 "Transtech Innovations" 507 "ISOBUS Test Center" 506 "IHI STAR Machinery Corporation" 505 "Yetter Farm Equipment" 504 "Vesper Marine" 503 "Naviop S.R.L." 502 "Attwood Corporation" 501 "Agrotronix S.A." 500 "Oxbo International Corporation" 499 "LCJ Capteurs" 498 "Innovative Design Solutions, Inc." 497 "SENTRON Sistemas Embarcados" 496 "W. Gessmann GmbH" 495 "HOLMER Maschinenbau GmbH" 494 "Synerject" 493 "Watcheye" 492 "Inergy Automotive Systems" 491 "Penny and Giles Ltd" 490 "QuikQ" 489 "Appareo Systems, LLC" 488 "The Charles Machine Works, Inc." 487 "DSE Test Solutions A/S" 486 "Westport Innovations Inc." 485 "MATT automotive" 484 "Headsight Inc." 483 "Valeo" 482 "Tricon Electronics" 481 "Chetco Digital Instruments" 480 "EnerDel, Inc." 479 "Vapor Bus International" 478 "OceanSat B.V." 477 "OilQuick AB" 476 "Hummingbird Marine Electronics" 475 "GME" 474 "Persen Technologies Inc." 473 "Boss Industries, Inc." 472 "Tenneco Inc." 471 "Sea Cross Marine AB" 470 "SI-TEX Marine Electronics" 469 "RA Consulting GmbH" 468 "Tyco Fire Protection Products" 467 "Lely Industries N.V." 466 "Veethree Electronics and Marine LLC" 465 "Ashcroft Inc" 464 "Leach International Corporation" 463 "PROBOTIQ" 462 "IHI Shibaura Machinery Corporation" 461 "HAWE Hydraulik SE" 460 "San Giorgio S.E.I.N." 459 "Alltek Marine Electronics Corp" 458 "Control Solutions, Inc." 457 "RUSELPROM-ElectricDrive Ltd" 456 "General Kinetics" 455 "ADZ NAGANO GmbH" 454 "NGK Spark Plug Co. Ltd" 453 "Cooper Bussmann" 452 "WIKA Alexander Wiegand SE & Co. KG" 451 "Parker Hannifin Corp" 450 "Dycor Technologies Ltd." 449 "Polaris Industries Inc" 448 "Stanadyne Corporation, Electronics Systems" 447 "Great Plains Mfg." 446 "CertTech, L.L.C." 445 "KAT MECHATRONIC, Electronic Product Division" 444 "ITT Power Solutions" 443 "SignalQuest, Inc." 442 "Horsch Maschinen GmbH" 441 "PTG Reifendruckregelsysteme GmbH" 440 "Cummins Power Generation" 438 "Comar Systems Ltd" 437 "Digital Yacht Limited" 436 "Kinze Manufacturing" 435 "Zunhammer GmbH" 434 "Stored Energy Systems" 433 "Rowe Electronics" 432 "S&A Systems, Inc." 431 "Tohatsu Corporation" 430 "Auteq Telematica S.A." 429 "Rota Engineering Ltd." 425 "Methode Electronics Inc, MDI" 424 "Odyne LLC" 423 "BSM Wireless, Inc." 422 "True Heading AB" 421 "Vertex Standard Co, Ltd" 420 "Vermeer Corporation, ACS Group" 419 "Fusion Electronics Ltd" 418 "Intellistick Inc" 417 "KZValve" 416 "Kubota Corporation" 415 "Valid Manufacturing Ltd." 414 "Cattron Group International" 413 "Datapross Nijbroek bv" 412 "WebTech Wireless Inc." 411 "Hy-Drive Technologies Ltd." 410 "COBO S.p.A. Divisione 3B6" 409 "Transfluid S.r.L." 408 "Corvus Energy Ltd." 407 "Comtech Mobile Datacom" 406 "Vecima Networks Inc." 405 "Wema System AS" 404 "Com Nav Marine Ltd" 403 "Trackwell ADS, Inc." 402 "Simma Software, Inc." 401 "Torqeedo GmbH" 400 "Livorsi Marine" 399 "ISEKI & Co., Ltd." 398 "Hilite International" 397 "Sanyo-kiki Co Ltd." 396 "Beyond Measure" 395 "GENTEC S.R.L." 394 "Capi 2 Nederland B.V." 393 "Harvest Tec, Inc" 392 "Tianyuan Technology Co Ltd." 391 "Electronic Design for Industry, Inc" 390 "Partech Inc." 389 "Benchmark Electronics, Minnesota Division" 388 "Innomatix, LLC" 387 "Orscheln Products, LLC" 386 "JLG Automation BVBA" 385 "Johnson Outdoor Marine Electronics" 384 "Camano Light" 383 "MCL Industries" 382 "National Agriculture and Food Research Organization" 381 "B & G" 380 "Suntech International Ltd." 379 "Yamabiko Corporation" 378 "Glendinning Marine Products" 377 "ifm electronic gmbh" 376 "Quake Global" 375 "Williams Controls Inc." 374 "Northern Lights, Inc." 373 "Electronic Design Inc." 372 "Delphi" 371 "Heinzmann GmbH & Co. KG" 370 "Rolls-Royce Marine AS" 369 "Power Torque Engineering Ltd" 368 "HANSENHOF_electronic" 367 "Fliegl Agrartechnik" 366 "Viewnyx Corp." 365 "Digi-Star, LLC" 364 "OEM Controls Inc." 363 "BEI Duncan" 362 "Poettinger Landtechnik GmbH (formerly Alois Poettinger Maschinenfabrik GmbH)" 361 "InMach" 360 "HJS Emission Technology GmbH & Co KG   (formerly HJS Fahrzeugtechnik GmbH & Co KG)" 359 "Ludwig Bergmann GmbH" 358 "Victron Energy B.V." 357 "Hardi International A/S" 356 "Fischer Panda Generators, Inc" 355 "Mastervolt International B.V." 354 "Junkkari OY" 353 "Hegemon Electronics, Inc." 352 "SAME DEUTZ-FAHR GROUP S.p.A." 351 "Thrane & Thrane" 350 "Noris Marine Systems GmbH & Co KG" 349 "Suonentieto" 348 "Amazonen Werke H. Dreyer" 347 "Honeywell" 346 "Control Solutions" 345 "Korean Maritime University" 344 "Parvus Corporation" 343 "Baumer Group" 342 "THOMAS MAGNETE GmbH" 341 "Boning GmbH & Co" 340 "Continental AG" 339 "Competence Center ISOBUS e.V." 338 "GRAF-SYTECO" 184 "EIA Electronics" 183 "KDS Controls, Inc" 182 "Vehicle Systems Engineering B.V." 181 "Coretronics, Inc." 180 "Smart Power Systems" 179 "TeeJet Technologies Springfield (formerly Midwest Technologies Illinois, LLC)" 178 "Continental Automotive GmbH (formerly Siemens VDO Automotive AG)" 177 "Diagnostic Systems Associates" 176 "Moritz Aerospace" 175 "Veris Technologies, Inc." 174 "AB Volvo Penta" 173 "Ryeso, Inc." 172 "Yanmar Co., Ltd. (formerly Yanmar Marine USA)" 171 "Topcon Electronics GmbH & Co. KG (formerly Wachendorff Elektronik GmbH & Co. KG)" 170 "Computronics Corporation Ltd." 169 "Marlin Technologies Inc." 168 "Xantrex" 167 "JLG Industries Inc" 166 "John Deere Electronic Solutions (formerly Phoenix International)" 165 "CPAC Systems AB" 164 "MTU Friedrichshafen GmbH (formerly DaimlerChrysler Off-Highway)" 163 "BRP Inc." 162 "Axiomatic Technologies" 161 "Offshore Systems (UK) Ltd" 160 "Nido" 159 "NTech Industries Inc" 158 "Firestone Industrial Products Company" 157 "ISSPRO Inc." 156 "ITT Industries - Cannon" 155 "Vetronix Corporation" 154 "Westerbeke Corporation" 153 "Woodward, Industrial Controls Division" 152 "elobau GmbH & Co. KG" 151 "Raven Industries, Inc." 150 "Fleetguard" 149 "Holset" 148 "Blue Water Data, Inc." 147 "Nautibus electronic GmbH" 146 "Maxima Technologies" 145 "MurCal Controls" 144 "Mercury Marine" 143 "W. Gmeiner GmbH & Co." 142 "TRW Automotive (Commercial Steering Systems)" 141 "Thales Navigation Ltd." 140 "Lowrance Electronics, Inc." 97 "Ag Leader Technology, Inc." 96 "Mech@tronic IT GmbH" 95 "Pacific Insight Electronics Corp." 94 "CNH Industrial N.V. (formerly CNH Global N.V.)" 93 "Perkins Engines Company Ltd." 92 "Ag-Chem Equipment Co., Inc." 91 "BSG Bodensee Steuergeraete GmbH" 90 "Knorr-Bremse SfN GmbH" 89 "Kverneland Group, Electronics Division" 88 "Hemisphere GPS Inc (formerly Satloc Precision GPS)" 87 "J.C. Bamford Excavators Ltd (JCB)" 86 "C. E. Niehoff & Company" 85 "Kohler Co" 84 "New Holland UK Limited" 83 "Bendix VORAD Technologies (formerly Eaton VORAD Technologies)" 82 "Bobcat/Ingersoll-Rand (formerly Melroe/Ingersoll-Rand)" 81 "Fire Research Corp." 80 "Twin Disc, Inc." 79 "Daimler Benz AG - Engine Division (PBM)" 78 "Frank W. Murphy Manufacturing, Inc" 77 "Deere Power Systems Group" 76 "unused (formerly Deere & Co, Construction Division)" 75 "Deere & Co, Agricultural Division" 74 "Eaton Axle-Brake Division" 73 "LeTourneau, Inc." 72 "Sisu Corporation" 71 "Vansco Electronics Ltd." 70 "Flex-coil Limited" 69 "Trimble Navigation" 68 "Scania" 67 "John Deere Coffeyville Works (formerly Funk Manufacturing Company)" 66 "John Deere Construction Equipment Division" 65 "MAN Nutzfahrzeuge AG" 64 "Unused (formerly SpectraPrecision Laserplane, then SpectraPhysics)" 63 "ZF Industries Inc." 62 "Wabco" 61 "Volvo Truck Corp." 60 "Volvo Trucks North America Inc." 59 "VES Inc." 58 "SPX Corporation, OTC Div" 57 "Danfoss  (formerly Sauer Sundstrand Co, then Sauer-Danfoss Co)" 337 "Carraro S.p.A." 336 "APE s.r.o." 335 "Evo Electric Ltd" 334 "Takata-Petri AG" 333 "Link Manufacturing, Ltd. (formerly Hadley Products Corporation)" 332 "HWH Corporation" 331 "Horton, Inc." 330 "Kidde Aerospace and Defense" 329 "Deif A/S" 328 "Qwerty Electronik AB" 327 "Sonceboz SA" 326 "Akron Brass Company" 325 "ASM Automation Sensorik Messtechnik GmbH" 324 "Snap-on Diagnostics" 323 "Mobileye Vision Technologies Ltd." 322 "MICHENKA s.r.o." 321 "Ultra Electronics, Electrics" 320 "Miedema Landbouwwerktuigenfabriek B.V." 319 "Cadec Global" 318 "SAT Plan" 317 "Navtronics Bvba" 316 "ITT Flow Control" 315 "Icom Incorporated" 314 "CSM GmbH" 313 "Ilmor Engineering, Inc." 312 "Lectronix, Inc." 311 "Patrick Power Products" 310 "TECNORD srl" 309 "Krauss-Maffei Wegmann GmbH & Co. KG" 308 "Cyntrx" 307 "MAS Technologies" 306 "Sleipner Motor AB" 305 "NovAtel Inc" 304 "EmpirBus AB" 303 "CTS Corporation" 302 "Nissin Kogyo Co., LTD" 301 "Parker Hannifin (UK) Ltd FDE group" 300 "Systron Donner Automotive" 299 "Rauch" 298 "Holley Performance" 297 "Zonar Systems Inc" 296 "micro dynamics GmbH" 295 "BEP Marine" 294 "Grayhill Inc." 293 "Spyder Controls Corp." 292 "IKUSI - Angel Iglesias S.A." 291 "Groeneveld Transport Efficiency BV" 290 "Kuebler GmbH" 289 "Watlow" 288 "Mitsubishi FUSO Truck & Bus Corp." 287 "NTech Industries, Inc" 286 "Coelmo srl" 285 "Sea Recovery Corp" 284 "Mobile Tech Chile" 283 "CWF Hamilton & Co Ltd" 282 "Medallion Instrumentation Systems" 281 "Precision Governors LLC" 280 "Leica Geosystems Pty Ltd" 279 "Geometris LP" 278 "Takata Electronics" 277 "LHP Telematics" 276 "Aqua-Hot Heating Systems" 275 "Navico Egersund AS" 274 "LTW Technology Co., LTD" 273 "Active Research Limited" 272 "Gross Mechanical Laboratories, Inc" 271 "Cole Hersee" 270 "Tennant" 269 "Saft America Inc.,  Space & Defense Division" 268 "Accurate Technologies" 267 "Red Lion Controls, Inc" 266 "International Thermal Research Ltd" 265 "MTS Sensor Technologie GmbH" 264 "Autolync" 263 "IMMI" 262 "HydraForce, Inc" 261 "Red Dot Corporation" 260 "Reichhardt GmbH Steuerungstechnik" 259 "Bucher Automation AG (formerly Jetter AG)" 258 "ARAG" 257 "Honda Motor Co., Ltd" 256 "Tyco Electronics AMP" 255 "MEAS France" 254 "GE Sensing" 253 "Mobile Control Systems" 252 "Sensor-Technik Wiedemann GmbH" 251 "German Agricultural Society, Test Center (DLG)" 250 "Kuhn Group" 249 "Schaltbau GmbH" 248 "Cooper Standard Automotive Active Systems Group" 247 "ePULSE" 246 "Class 1, Inc" 245 "Capstan Ag Systems, Inc." 244 "Techno-Matic" 243 "eRide, Inc." 242 "Kokusandenki Co. Ltd" 241 "Schneider Automation SAS" 240 "Vanair Manufacturing" 239 "May & Scofield Ltd" 238 "ZF Friedrichshafen AG" 237 "Agtron Enterprises Inc" 236 "NORAC Systems International Inc" 235 "SailorMade Marine Telemetry - Tetra Technology Ltd." 234 "Mondial electronic GmbH" 233 "Yacht Monitoring Solutions Inc." 232 "TSD Integrated Controls" 231 "Topcon Positioning Systems, Inc." 230 "Saucon Technologies" 229 "Garmin International Inc." 228 "Unused (formerly ZF Marine Electronics)" 227 "Lykketronic A/S" 226 "Monaco Coach Corporation" 225 "SKF" 224 "EMMI Network, S.L." 223 "Vaueo Retarder Co., Ltd." 222 "Generac Power Systems, Inc." 221 "SiE" 220 "Beede Electrical Instrument Company, Inc" 219 "Cat OEM Solutions" 218 "Gits Manufacturing Company" 217 "RM Michaelides Software & Elektronik GmbH" 216 "Paneltronics Inc." 215 "Aetna Engineering/Fireboy-Xintex" 214 "MC elettronica Srl" 213 "CNH Belgium N.V." 212 "Sure Power Industries, Inc" 211 "DNA Group" 210 "Iteris, Inc." 209 "Bell Equip. Co. SA (PTY) LTD" 208 "Drew Technologies, Inc" 207 "Otto Engineering" 206 "port GmbH" 205 "SmarTire Systems Inc" 204 "The Morey Corporation" 203 "MILtronik GmbH" 202 "Curtis Instruments, Inc" 201 "Disenos y Tecnologia S.A." 200 "MGM Brakes" 199 "ACTIA Group (formerly Actia Corp)" 198 "Mystic Valley Communications" 197 "Mechron Power Systems" 196 "LEMKEN GmbH & Co KG" 195 "General Engine Products" 194 "TriMark Corporation" 193 "Jeppesen Marine" 192 "Floscan" 191 "XRS Corporation (formerly XATA Corporation)" 190 "Hella KGaA Hueck & Co" 189 "QUALCOMM" 188 "EMP Corp" 187 "Air-Weigh" 186 "Altronic, Inc" 185 "Beede Electrical Instrument Company" 139 "Caterpillar Trimble Control Technologies (CTCT), LLC" 138 "Georg Fritzmeier GmbH & Co. KG" 137 "Littelfuse, Inc (formerly Maretron)" 136 "Komatsu Ltd" 135 "Airmar Technology Corporation" 134 "Iris Technology Ltd" 133 "Bucher Schoerling GmbH" 132 "Mulag-Fahrzeugwerk" 131 "ITT Industries" 130 "Nido - Universal Machines B.V." 129 "OMNEX Control Systems Inc." 128 "Gerhard Duecker GmbH & Co. KG" 127 "Holland USA" 126 "Driver Tech" 125 "Nevada Automotive Test Center" 124 "Hydac Electronic" 123 "Basler Electric" 122 "FG Wilson (Engineering) Limited" 121 "HED (Hydro Electronic Devices, Inc.)" 120 "RDS Technology Ltd" 119 "IntegriNautics  " 118 "Intron GmbH" 117 "HUSCO International" 116 "BEELINE Technologies" 115 "NACCO Materials Handling Group, Inc." 114 "EControls, Inc." 113 "Stress-Tek, Inc." 112 "MECALAC" 111 "Bernard Krone Holding SE & Co. KG (formerly Maschinenfabrik Bernard Krone GmbH)" 110 "EPIQ Sensor-Nite" 109 "TeeJet Technologies Denmark (formerly LH Technologies ApS)" 108 "PTx Trimble (formerly WTK-Elecktronik GmbH, now a duplicate entry; use MFR ID 98)" 107 "Grimme Landmaschinen GmbH & Co. KG" 106 "BAE Systems Controls, Inc." 105 "Kiepe Elektrik GmbH & Co. KG" 104 "CLAAS KGaA mbH (formerly CLAAS Selbstfahrende Erntemaschinen GmbH)" 103 "CLAAS E-Systems GmbH (formerly CLAAS E-Systems KGaA mbH & Co. KG)" 102 "AGCO (formerly AGCO GmbH & Co.)" 101 "Sensoria" 100 "VDO Technik AG" 99 "International Transmissions Ltd (ITL)" 98 "PTx Trimble (formerly Mueller-Elektronik GmbH & Co)" 56 "SAIC" 55 "Ryder System Inc." 54 "Meritor Wabco" 53 "Continental Automotive Systems US, Inc. (formerly Rockwell Land Transportation)" 52 "Meritor Automotive, Inc. (formerly Rockwell Automotive)" 51 "Robert Bosch GmbH" 50 "Robert Bosch Corp" 49 "RE America Inc." 48 "Pollak Alphabet" 47 "Phillips Semiconductor" 46 "Noregon Systems, LLC  (formerly Noregon Systems, Inc)" 45 "PACCAR" 44 "Nippondenso Co. Ltd." 43 "International Truck and Engine Corporation - Vehicle Electronics (formerly Navistar Intl Trans Corp.)" 42 "International Truck and Engine Corporation - Engine Electronics  (formerly Navistar Intl Trans Co., Engine Electronics)" 41 "Motorola Inc." 40 "Motorola AIEG Inc." 39 "Microfirm Inc." 38 "Micro Processor Systems Inc." 37 "Mack Trucks Inc." 36 "Lucas Ind." 35 "Kenworth Truck Co." 34 "Kelsey Hayes Co." 33 "John Deere" 32 "Jacobs Vehicle Systems" 31 "J Pollak Corp" 30 "Isuzu Motors Ltd" 29 "Hino Motors Ltd." 28 "Grote Ind. Inc." 27 "GMC" 26 "General Motors Corp, Service Technology Grp" 25 "Daimler Trucks North America LLC (formerly Freightliner LLC)" 24 "Ford Motor Co., Vehicle Controls" 23 "Ford Motor Co., Heavy Truck" 22 "Ford Motor Co., Electronic Concepts & Systems" 21 "Echlin Inc., Midland Brake Inc." 20 "Eaton Ltd" 19 "Eaton Corp. Trucking Info Services" 18 "Eaton Corp, Transmission Div." 17 "Eaton Corp, Corp Res & Dev" 16 "Eaton Corp" 15 "DICKEY-john Corporation" 14 "Detroit Diesel Corporation" 13 "Delco Electronics" 12 "Deere & Company, Precision Farming" 11 "Dearborn Group Inc." 10 "Cummins Inc (formerly Cummins Engine Co)" 9 "Chrysler Corp." 8 "Caterpillar Inc." 7 "Case Corp." 6 "Berifors Electronics AB" 5 "AMP Inc." 4 "Ametek-Dixson" 3 "Ametek, US Gauge Division" 2 "Allison Transmission, Inc." 1 "Bendix Commercial Vehicle Systems LLC (formerly Allied Signal Inc.)" 0 "Reserved" ;
VAL_ 2566838526 VehicleSystem5 127 "Not Available" 0 "Ind. Process Control Stationary" ;
VAL_ 2566838526 VehicleSystem4 125 "Entertainment" 120 "Display" 85 "External Environment" 75 "Sensor Communication Interface" 35 "Electrical Generation" 100 "Deck, Cargo and Fishing Equipment" 90 "Internal Environment" 80 "Instrumentation/General Systems (deprecate)" 70 "Communications" 60 "Navigation" 50 "Propulsion" 40 "Steering and Control Surfaces" 30 "Electrical Distribution" 25 "Inter/Intranetwork Device" 20 "Safety Systems" 10 "System Tools" 127 "Not Available" 0 "Non-specific System" ;
VAL_ 2566838526 VehicleSystem3 8 "Grader" 7 "Four Wheel Drive Loader" 6 "Forklift" 5 "Excavator" 4 "Crawler" 3 "Backhoe" 2 "Articulated Dump Truck" 1 "Skid Steer Loader" 127 "Not Available" 0 "Non-specific System" ;
VAL_ 2566838526 VehicleSystem2 25 "Slurry Applicators" 24 "Utility Vehicles" 23 "Mulchers" 22 "Timber Processing Machines" 21 "Timber loaders" 20 "Forwarders" 19 "Timber Harvesters" 17 "Sensor Systems" 16 "Skidder" 15 "Earth Work" 14 "Special Crops" 13 "Powered Auxiliary Device" 12 "Farm Yard Operations" 11 "Transport/Trailer" 10 "Irrigation" 9 "Forage" 8 "Root Harvesters" 7 "Harvesters" 6 "Sprayers" 5 "Fertilizers" 4 "Planters/Seeders" 3 "Secondary Tillage" 2 "Tillage" 1 "Tractor" 127 "Not Available" 0 "Non-specific System" ;
VAL_ 2566838526 VehicleSystem1 2 "Trailer" 1 "Tractor" 127 "Not Available" 0 "Non-specific System" ;
VAL_ 2565799678 IndustryGroup 6 "Reserved for SAE" 7 "Reserved for SAE" 5 "IndustrialProcessCtrlStationary" 4 "Marine" 3 "Construction" 2 "Agricultural and Forestry" 1 "On-Highway" 0 "Global" ;
VAL_ 2565799678 Function 127 "Reserved" 126 "Reserved" 125 "Reserved" 124 "Reserved" 123 "Reserved" 122 "Reserved" 121 "Reserved" 120 "Reserved" 119 "Reserved" 118 "Reserved" 117 "Reserved" 116 "Reserved" 115 "Reserved" 114 "Reserved" 113 "Reserved" 112 "Reserved" 111 "Reserved" 110 "Reserved" 109 "Reserved" 108 "Reserved" 107 "Reserved" 106 "Reserved" 105 "Reserved" 104 "Reserved" 103 "Reserved" 102 "Reserved" 101 "Reserved" 42 "Water Pump Control" 41 "Lighting - Operator Controls" 40 "Seat Control" 39 "Ignition Control Module" 38 "Tire Pressure Control" 37 "Cab Controller" 36 "Pneumatic - System Controller" 35 "Suspension - System Controller" 34 "Hydraulic Pump Controller" 33 "System Monitor" 32 "Headway Controller" 31 "Propulsion Battery Charger" 30 "Management Computer" 29 "Virtual Terminal (in cab)" 28 "Off Vehicle Gateway" 27 "Power TakeOff (Secondary or Front)" 26 "Body Controller" 25 "Network Interconnect ECU" 24 "Vehicle Security" 23 "Vehicle Navigation" 22 "Aerodynamic Control" 21 "Cab Climate Control" 20 "Trip Recorder" 19 "Instrument Cluster" 18 "Suspension - Drive Axle" 17 "Suspension - Steer Axle" 16 "Steering Controller" 15 "Fuel System" 14 "Cruise Control" 13 "Retarder - Driveline" 12 "Retarder - Engine" 11 "Brakes - Drive Axle" 10 "Brakes - Steer Axle" 9 "Brakes - System Controller" 8 "Axle - Drive" 7 "Axle - Steering" 6 "Power TakeOff - (Main or Rear)" 5 "Shift Control/Console" 4 "Battery Pack Monitor" 3 "Transmission" 2 "Electric Propulsion Control" 1 "Auxiliary Power Unit (APU)" 0 "Engine" 100 "Reserved" 99 "Reserved" 98 "Reserved" 97 "Reserved" 96 "Reserved" 95 "Reserved" 94 "Auxiliary Display" 93 "Fuel Cell System" 92 "Current Sensor" 91 "Accessory Electric Motor Controller" 90 "Vehicle Adapter Communication Controller (VACC)" 89 "Supply Equipment Communication Controller (SECC)" 88 "Electric Power Converter" 87 "Driver Impairment Device" 86 "EV Communication Controller" 85 "Engine Injection Control Module" 84 "Start Aid Device" 83 "Printer" 82 "File Server" 81 "Hydraulic Powertrain" 80 "Electric Powertrain" 79 "Power Systems Manager" 78 "Fire Suppression System" 77 "Fuel Properties Sensor" 76 "Temperature Sensor" 75 "Supplemental Fan" 74 "Lubrication System" 73 "Rollover Detection Control" 72 "Coolant Valve Controller" 71 "Transfer Case Control" 70 "Auxiliary Regeneration Device" 69 "Engine Emission Aftertreatement System" 68 "Aftertreatment system gas measurement" 67 "Electrical System Controller" 66 "I/O Controller" 65 "Gas Flow Measurement" 64 "Endurance Braking" 63 "Engine Valve Controller" 62 "On-Board Diagnostic Unit" 61 "File Server/Printer" 60 "Cab Display" 59 "Starter" 58 "Fan Drive Control" 57 "Steering Column Unit" 56 "Communications Unit, Radio" 55 "Communications Unit, Satellite" 54 "Communications Unit, Cellular" 53 "Alternator/Charging System" 52 "Chassis Controller" 51 "Forward-Looking Collision Warning System" 50 "Auxiliary Heater" 49 "Clutch/Converter Control" 48 "Ramp Control" 47 "Information System Controller" 46 "Oil Sensor Unit" 45 "Vehicle Dynamic Stability Control" 44 "Exhaust Emission Control" 43 "Transmission Display" ;
VAL_ 2565799678 ManufacturerCode 1410 "Allan Equipment Manufacturing Ltd." 1409 "Z Elektronika Kft." 1408 "Lenco Marine Inc." 1407 "Open-Agriculture" 1406 "Lumilex ALT SRL" 1405 "TELIG Electronics" 1404 "BRUSA HyPower AG" 1403 "Arco Marine" 1402 "ComNav Technology Ltd." 1401 "ROM Communications Inc." 1400 "IWN GmbH & Co. KG" 1399 "Hans Brantner & Sohn Fahrzeugbaugesellschaft mbH" 1398 "Gobius Sensor Technology AB" 1397 "SaMASZ Sp. Z o.o." 1396 "Fast Ag Solutions, LLC" 1395 "MLB Industrial" 1394 "Zhejiang Ruixing Electromechanical Technology Co., Ltd." 1393 "Powerland Technology Inc" 1392 "Phoenix America LLC" 1391 "AriensCo" 1390 "FJ Dynamics International Limited" 1389 "EVEX Co., LTD" 1388 "Nira Technology" 1387 "Radel (Pty) Ltd" 1386 "Smart Eye AB" 1385 "Pro Charging Systems, LLC" 1384 "Tecnoseal Foundry S.r.l." 1383 "Alpego S.p.A." 1382 "Thornwave Labs Inc." 1381 "Dr. Diesel Technologies" 1380 "ADVES GmbH & Co. KG" 1379 "Novag SAS" 1378 "Bertini SA" 1377 "ABD Solutions" 1376 "SUNS International, LLC" 1375 "ŠKODA ELECTRIC a.s." 1374 "CASAPPA S.p.A." 1373 "Centek Industries" 1372 "Elco Motor Yachts" 1371 "First Mode" 1370 "Emtech S.A." 1369 "Electric Yacht" 1368 "RAD Propulsion Ltd" 1367 "Dewulf NV" 1366 "Telemecanique Sensors & Switches" 1365 "JVCKENWOOD Corporation" 1364 "Yashu Systems" 1363 "Calix AB" 1362 "Zparq AB" 1361 "Nantong Saiyang Electronics Co., Ltd." 1360 "Lemca Vision" 1359 "BlueNav" 1358 "Fontaine Fifth Wheel" 1357 "TireCheck" 1863 "Thomas G. Faria Co." 1862 "Sanshin" 1861 "Vector North America (formerly Vector Cantech)" 1860 "MMP" 1859 "Kvaser AB" 1858 "Litton" 1857 "Simrad" 1856 "Trimble" 1855 "Furuno USA" 1854 "Northstar Technologies" 1853 "Japan Radio Co" 1852 "Navionics" 1851 "RayMarine" 1850 "Seastar Solutions (formerly Teleflex)" 1569 "621 Technologies Inc." 1551 "LMCE Group" 1550 "Mario Tanzi S.A." 1549 "AM Co., Ltd." 1546 "ESMART" 1545 "RoadEazy" 1544 "Geophysical Survey Systems, Inc." 1543 "GT Joysticks AG" 1542 "Global Digital Instruments" 1541 "Solid State Marine" 1540 "Ideas & Motion" 1539 "Ceday Information Technologies" 1538 "Quick S.p.A." 1537 "Anyload Weigh & Measure Inc." 1536 "Tatra Trucks a.s." 1535 "LOX Container Technology AB" 1534 "BluVein" 1533 "Rieker Inc." 1532 "E-Switch, Inc." 1531 "Kobelco Construction Machinery Co.,Ltd." 1530 "Roelama B.V." 1529 "Industrie Elektronik Brilon GmbH" 1528 "Savant Technology" 1527 "Richardt Steuer- und Regelgeraete GmbH" 1526 "MITSUBISHI MAHINDRA AGRICULTURAL MACHINERY CO.,LTD." 1525 "Emsiso-emDrive" 1524 "Ocean Infinity Solutions Limited" 1523 "Carlson Software" 1522 "American Thermal Instruments" 1521 "Agricolmeccanica" 1520 "SRT Marine Systems PLC" 1519 "Volboff Electron Science and Technology Co., Ltd." 1518 "Nova Kool Manufacturing ULC" 1517 "Daedong Corporation" 1516 "THERMIS spol. s r.o." 1515 "Ingeniería y Sistemas Cerea" 1514 "SYMX.ai" 1513 "Sy-Klone International" 1512 "Lumitec LLC" 1511 "APATOR METRA s.r.o." 1510 "Austin Motor Works" 1509 "Bondioli & Pavesi" 1508 "Xwatch Safety Solutions Ltd. part of Hexagon" 1507 "Apex.AI, Inc." 1506 "Expion360" 1505 "BC Motion" 1504 "Nimbus Power Systems, Inc." 1503 "Rosemount Specialty Products" 1502 "Barantech" 1501 "Reverso Pumps LLC" 1500 "Scanstrut Inc." 1499 "Hydrasystem SP. Z O.O." 1498 "PM Pfanzelt Maschinenbau GmbH" 1497 "ERMO Spa" 1496 "AgriRobot" 1495 "FlyAgData" 1494 "RAPITRONICS" 1493 "Jantop Oy" 1492 "Softivert" 1491 "Power Pollen" 1490 "Clean Republic SODO, LLC" 1489 "Lite-Check LLC" 1488 "Boetkin Technology Co., LTD" 1487 "Geosoft" 1486 "Xpanner" 1485 "Lester Electrical" 1484 "AgroOSA" 1483 "Nanjing Sandemarine Information Technology Co., Ltd." 1482 "CMC Marine" 1481 "E-Force Marine" 1480 "Thermo King" 1479 "A-Electronix" 1478 "Alps Alpine Co., Ltd." 1477 "TOBROCO-GIANT" 1476 "Wilhelm Stoll Maschinenfabrik GmbH" 1475 "DSP Solutions, Inc." 1474 "Calex Electronics Limited" 1473 "Cranesmart Systems, Inc." 1472 "Acculon Energy" 1471 "FT Technologies" 1470 "GemOne NV" 1469 "LS Mtron" 1468 "Senquip" 1467 "S.A.E.T. s.r.l." 1466 "Sveaverken Svea Agri AB" 1465 "Watteco" 1464 "Hi-Target Surveying Instrument Co., Ltd." 1463 "STOK Electric" 1462 "Trackunit ApS" 1461 "Vanquish Yachts" 1460 "Tocaro Blue" 1459 "Advanced Input Systems" 1458 "RideController LLC" 1457 "Albach Maschinenbau AG" 1456 "Krampe Fahrzeugbau GmbH" 1455 "Eberspächer Climate Control Systems International GmbH" 1454 "QTIS B.V." 1453 "Vital Battery" 1452 "Micro-Air LLC" 1451 "Guangdong ePropulsion Technology Ltd." 1450 "Agrivaux" 1449 "Bontaz Centre" 1448 "Elmer's Manufacturing" 1447 "Innotag Distributions Inc." 1446 "Roswell Marine" 1445 "Starboard Yacht Group" 1444 "Micropower Group" 1443 "SoilEssentials Limited" 1442 "EVYTRA GmbH" 1441 "Shanghai Allynav Technology Co.,Ltd." 1440 "Egis Mobile Electric" 1439 "PredictWind Ltd" 1438 "Aeolionics" 1437 "DOKEN Technology Co. Ltd." 1436 "M-extend" 1435 "Heilongjiang Huida Technology Co., Ltd" 1434 "eSurvey GNSS Ltd." 1433 "Unicontrol ApS" 1432 "MDH Defence Ltd." 1431 "Nauto Inc." 1430 "Mantracourt Electronics Ltd" 1429 "Nikola Corporation" 1428 "Samo Maschinenbau GmbH" 1427 "REITER RESPIRO" 1426 "Samson Group" 1425 "Electronics in Agriculture, School of Engineering, University of Galway" 1424 "Bewis" 1423 "AC S.A." 1422 "xTCU AG" 1421 "Clarios, LLC" 1420 "TALOS - Precision Measurement Technologies" 1419 "iPatch Marine" 1418 "Karluna Engineering" 1417 "Revatek LLC" 1416 "Wavetronix LLC" 1415 "Máquinas Agrícolas Jacto S.A." 1414 "INTRACOM DEFENSE S.A." 1413 "OHNOH2O LLC" 1412 "Naocontrol S.L." 1411 "Shanghai Huace Navigation Technology Ltd." 1356 "Nordic Lights Ltd" 1355 "DROP Agricultura Ltda" 1354 "Técnicas de Electrónica y Automatismos, S.A." 1353 "Ocean LED Marine Ltd" 1352 "NISHIYAMA Corporation" 1351 "Motorenfabrik Hatz GmbH & Co. KG" 1350 "AGRONETIC" 1349 "ANNABURGER Nutzfahrzeug GmbH" 1348 "Radian IoT, Inc." 1347 "Munckhof Fruit Tech Innovators" 1346 "Einboeck GmbH" 1345 "PRIGNITZ Mikrosystemtechnik GmbH" 1344 "Haulotte Group" 1343 "Heavy Data GmbH" 1342 "DKE-Data GmbH & Co. KG" 1341 "Ag Express Electronics" 1340 "ORELTEK Elektronik ve Yazilim Teknolojileri" 1339 "Tillett and Hague Technology Limited" 1338 "Volta Trucks AB" 1337 "Barnacle Systems Inc." 1336 "Aegis Power Systems, Inc." 1335 "CPDEVICE" 1334 "Greer Company" 1333 "xFarm Technologies SA" 1332 "Fairbanks Scales, Inc." 1331 "Dolphin Charger" 1330 "Warwick Control Technologies" 1329 "IDM S.r.l." 1328 "PerPlant ApS" 1327 "Frans Vervaet B.V." 1326 "HBC-radiomatic GmbH" 1325 "OPW (formerly BASE Engineering Inc.)" 1324 "Bourgault Industries" 1323 "Briter Products, Inc." 1322 "Movimatica" 1321 "PATLITE Corporation" 1320 "Triskel Marine Ltd" 1319 "I/O Controls Corporation" 1318 "Atlis Motor Vehicles" 1317 "GMM - Global Maritime Management GmbH" 1316 "Hinkley Yachts" 1315 "SMPC Technologies Ltd." 1314 "Newton Crouch Company, LLC" 1313 "United States Army - Ground Vehicle Systems Center" 1312 "Control Devices Pty Ltd" 1311 "Humphree AB" 1310 "LPL Systems (formerly Loughborough Projects Ltd)" 1309 "Shanghai Zhichuan Electronic Tech Co., Ltd." 1101 "DIS Sensors B.V." 1100 "LINK Marine Technologies (formerly Smart Yachts International Limited)" 1099 "MadgeTech, Inc" 1098 "Preh GmbH" 1097 "M2M Craft Co., Ltd" 1096 "Texense Sensors" 1095 "WEG Drives and Controls - Automação Ltda" 1094 "Tokushu Denki" 1093 "innolectric" 1092 "Scheiber" 1091 "Wheel Monitor Inc." 1090 "E-T-A Circuit Breakers Ltd" 1089 "Carrosserie HESS AG" 1088 "E-T-A Circuit Breakers" 1087 "ITPhotonics S.r.l." 1086 "Life Racing Ltd" 1085 "Wet Sounds, LLC" 1084 "Shadow-Caster LED lighting LLC" 1083 "Nauticoncept" 1082 "TÜMOSAN Engine and Tractor Co." 1081 "Imcon Electronics, s.r.o." 1080 "Epsilor-Electric Fuel Ltd." 1079 "Carl Zeiss Spectroscopy GmbH" 1078 "GE Appliances" 1077 "Ymer Technology" 1076 "DOGA S.A." 1075 "Uniden America Corporation" 1074 "Kindhelm / Navigs Oy" 1073 "Manitou Equipment America LLC" 1072 "La Marche Manufacturing Company" 1071 "MACH SYSTEMS s.r.o." 1070 "Quick-teck Electronics Ltd" 1069 "Lithionics Battery LLC" 1068 "Zapi S.p.A." 1067 "Tecomec S.r.l." 1066 "Spot Zero Water" 1065 "CALYPSO Instruments" 1064 "Omnitech Robotics Inc." 1063 "SolSteer" 1062 "Marol Co Ltd" 1061 "Volvo Construction Equipment" 1060 "Scale-Tec" 1059 "Boatrax" 1058 "Bondioli & Pavesi SpA" 1057 "EquipmentShare" 1056 "Lithium Pros" 1055 "EXA Computing GmbH" 1054 "Schmotzer Hacktechnik GmbH & Co. KG" 1053 "Vetus Maxwell, Inc." 1052 "Pfreundt" 1051 "ProNav AS" 1050 "Spacenus GmbH" 1049 "S&S Cycle" 1308 "Agtecnic" 1307 "Smart AG Systems" 1306 "Koden Electronics Co., Ltd." 1305 "dragonfly Energy" 1304 "Palfinger Europe GmbH" 1303 "Carbon Bee AgTech" 1302 "ProMariner" 1301 "Tecumseh do Brasil Ltda" 1300 "Watt Fuel Cell Corporation" 1299 "Energy Solutions" 1298 "SFOGGIA Agriculture Division S.r.l." 1297 "Micro-Epsilon Messtechnik GmbH & Co. KG" 1296 "Hexagon" 1295 "SIP d.d." 1294 "TR-Electronic GmbH" 1293 "POSITAL" 1292 "SUMITOMO CONSTRUCTION MACHINERY CO., LTD." 1291 "Forward Thinking Systems LLC" 1290 "WaveTamer Partners LLC" 1289 "Loadrite (Auckland) Ltd." 1288 "ANELLO Photonics" 1287 "Spartan Radar" 1286 "NEXAT GmbH" 1285 "Graco Inc." 1284 "Robot Makers GmbH" 1283 "LTG Tech" 1282 "COTEK ELECTRONIC IND. CO., LTD" 1281 "iQuus" 1280 "SANTEST CO., LTD." 1279 "Ognibene Power S.p.A." 1278 "Comrod Communication Group" 1277 "BMZ Germany GmbH" 1276 "Aspin Kemp & Associates" 1275 "O.M.P. Officine Mazzocco Pagnoni S.r.l." 1274 "LDL Technology" 1273 "Clearflame Engines Inc" 1272 "Samsara Inc." 1271 "Raven Connected" 1270 "Versalift Denmark A/S" 1269 "VIS Hydraulics s.r.l." 1268 "Back 40 Precision Inc." 1267 "Wacker Neuson SE" 1266 "Hyundai Doosan Infracore" 1265 "IPETRONIK GmbH & Co KG" 1264 "Microelect" 1263 "BOS Balance of Storage Systems AG" 1262 "Fort Robotics" 1261 "AgXeed" 1260 "Interactive Technologies, Inc." 1259 "Grayson Automotive Services Limited" 1258 "AGC Technologies" 1257 "KOSTAL" 1256 "Dimensions Agri Technologies AS" 1255 "Altec Industries, Inc." 1254 "ARADEX AG" 1253 "Trafag AG" 1252 "APV - Technische Produkte GmbH" 1251 "Valmet Automotive EV Power Ltd" 1250 "ELHO" 1249 "Integrated Power Solutions AG" 1248 "O.M.F.B. S.p.A. Hydraulic Components" 1247 "GRIFA" 1246 "Rother Industries & Technology" 1245 "Raritan Engineering Company, Inc" 1244 "Planti Center" 1243 "AvMap S.r.l." 1242 "Super Start Batteries" 1241 "Ineo Systrans" 1240 "TiMOTION" 1239 "SuperTrack Aps" 1238 "Honda Electronics Co., Ltd" 1237 "Changzhou Lambda Electronic Co., Ltd" 1236 "Agrosystem" 1235 "NESAN Automotive Inc." 1234 "American Battery Solutions" 1233 "nke Marine Electronics" 1232 "Treffler Maschinenbau GmbH & Co. KG" 1231 "Excidor AB" 1230 "Nick Abbey Digital Agriculture Ltd" 1229 "Arcon Designs, LLC" 1228 "INTILION GmbH" 1227 "YAHATA Co., Ltd." 1226 "Piippo Hydraulic" 1225 "SeedMaster Manufacturing Ltd" 1224 "Neuser Elektrotechnik GmbH" 1223 "Toyo Agricultural Machinery Manufacturing Co., Ltd" 1222 "Tough Tech Ltd." 1221 "Norcold Inc." 1220 "Catamaran Electronics LLC" 1219 "Weidmueller Interface GmbH & Co. KG" 1218 "Septentrio" 1217 "FSG Fernsteuergeräte Kurt Oelsch GmbH" 1216 "SMP Poland sp. z o.o." 1215 "Power Control Systems" 1214 "Element 1" 1213 "Apollo Tyres Ltd" 1212 "TAO Performance" 1211 "Kiwon Electronics Co., Ltd." 1210 "Ambra Solutions" 1209 "Bauser GmbH & Co. KG" 1208 "Afflield Kft. (MachineryGuide)" 1207 "UEC Electronics" 1206 "STE Solutions B.V." 1205 "Carbon Autonomous Robotic Systems" 1204 "Miller Technology Incorporated" 1203 "Equipment Technologies, Inc." 1202 "OSCAR ELECTRONICS SRL (formerly OSCAR Elettronica)" 1201 "Emisense Technologies, LLC" 1200 "Xinuo Information Technology (Xiamen) Corporation Limited" 1199 "ELEO Technologies B.V." 1198 "ComLink Equipamentos Eletrônicos Ltda" 1197 "SOLGE Corporation" 1196 "Terra Care GmbH" 1195 "düvelsdorf" 1194 "Sierra Marine" 1193 "emotas embedded communication GmbH" 1192 "Airmoniq Pro Kft." 1191 "Pacoma USA, Inc." 1190 "Sirros IoT" 1189 "Autotrasporti Cavallo G&V" 1188 "G-SNS" 1187 "TiTAN-Project LLC" 1186 "Sailmon BV" 1185 "WFCO Electronics" 1184 "AMA S.p.A." 1183 "Zipwake AB" 1182 "Rottmann Automation" 1181 "Banjo Corporation" 1180 "Murata Power Solutions Inc." 1179 "QS Control srl" 1178 "ERO GmbH" 1177 "RNG International Inc." 1176 "Asuns Corp." 1175 "MAGTEC Products, Inc." 1174 "Agricon GmbH" 1173 "philippi elektrische systeme gmbh" 1172 "Hyzon Motors" 1171 "Vista Manufacturing" 1170 "Poseidon Ocean Systems Ltd." 1169 "Sea Machine Robotics Inc." 1168 "Masats S.A." 1167 "Tevva Motors" 1166 "Wachendorff Automation GmbH & Co. KG" 1165 "InnoTotal AB" 1164 "SEG Automotive" 1163 "DFX Technologies LLC" 1162 "PEL-tuote Oy" 1161 "Griessbach GmbH" 1160 "MG Energy Systems B.V." 1159 "Bel Power Solutions" 1158 "Technoton Electronics" 1157 "Carriergistics" 1156 "Nokian Tyres" 1155 "LACOS GmbH (formerly LACOS Computerservice GmbH)" 1154 "TBS Electronics BV" 1153 "Kawasaki Heavy Industries, Ltd." 1152 "Vredo Dodewaard B.V." 1151 "Orca Technologies AS" 1150 "BSB Artificial Intelligence GmbH" 1149 "Wuxi Shengbang Electronics Co., Ltd" 1148 "Stercom Power Solutions GmbH" 1147 "Dana Inc." 1146 "Rometron" 1145 "Kiwi Yachting" 1144 "Troo Corporation" 1143 "Elektro-Szoft 2000" 1142 "Truma" 1141 "MRS Electronic GmbH & Co. KG" 1140 "Across Oceans Systems Ltd." 1139 "ASP Technology" 1138 "Micro-Sensor GmbH" 1137 "SIKO GmbH" 1136 "Primosensor GmbH" 1135 "Japan Aviation Electronics Industry, Limited" 1134 "Master Schools at Ostbahnhof" 1133 "MEGATRON Elektronik GmbH & Co. KG" 1132 "Tokachi Zaidan" 1131 "Guliwer electronics s.r.o." 1130 "Vitesco Technologies" 1129 "Spectrolytic GmbH" 1128 "Citoon Electronic Technology (Tianjin) Co., Ltd." 1127 "ElectroMaax" 1126 "Auralix" 1125 "Griffith-Elder & Co. Ltd." 1124 "Fortron Agriculture" 1123 "QP Hydraulics" 1122 "GT Inc." 1121 "Platform Science" 1120 "Elettromedia s.r.l." 1119 "Balmar LLC" 1118 "L3Harris ASV" 1117 "LG Chem, Ltd" 1116 "HR Agrartechnik GmbH" 1115 "Gems Sensors & Controls" 1114 "Bob's Machine" 1113 "iVolve Pty Ltd" 1112 "Bollinger Motors" 1111 "SEPPI M." 1110 "Analytic Systems Ware (1993) Ltd." 1109 "Dockmate" 1108 "ORBCOMM" 1107 "Dräger Safety" 1106 "Great Dane LLC" 1105 "Redekop Manufacturing" 1104 "The Toro Company" 1103 "Diesel Laptops" 1102 "Carl Geringhoff GmbH & Co. KG" 1048 "Agrivation UG" 1047 "Sonic Corporation" 1046 "Praxidyn" 1045 "CMR Group" 1044 "Xee" 1043 "Hyva" 1042 "engcon group" 1041 "EZ Lynk" 1040 "BPE Electronics Srl" 1039 "Liugong Dressta Machinery" 1038 "EMIT Technologies, Inc." 1037 "Dragonfly Energy Corp." 1036 "Bender GmbH & Co. KG" 1035 "Agres" 1034 "Siren Marine" 1033 "ECCO Safety Group" 1032 "SIMOL S.p.A." 1031 "Flintec UK Ltd." 1030 "Tume-Agri Oy" 1029 "The Marine Guardian LLC" 1028 "Autel Intelligent Technology Corp., Ltd" 1027 "Goldacres PTY LTD" 1026 "ZTR Control Systems, LLC" 1025 "eze System, Inc." 1024 "Inventus Power" 1023 "PEAK-System Technik GmbH" 1022 "ITC Inc" 1021 "Entratech Systems LLC" 1020 "Team Italia Marine srl (formerly Onyx Marine Automation s.r.l.)" 1019 "Codek Foundries" 1018 "Flex TTS" 1017 "Caldaro AB" 1016 "Röhren- und Pumpenwerk BAUER GmbH" 1015 "SECURITAG SAS" 1014 "Briri Maschinenbau GmbH" 1013 "Allochis E-Tec" 1012 "Rhodan Marine Systems of Florida LLC" 1011 "Soundmax Electronics Ltd" 1010 "Agricultural Industry Electronics Foundation e.V." 1009 "TouchTronics, Inc." 1008 "Lintest Systems LLC" 1007 "Maschinenfabrik Meyer-Lohne GmbH" 1006 "Proterra" 1005 "TSE Brakes, Inc." 1004 "Ultraflex SpA" 1003 "technotrans SE" 1002 "Kussmaul Electronics Co." 1001 "Cleral Inc." 1000 "Landmaschinen Wienhoff GmbH" 999 "TerraTroniq B.V." 998 "Transcell Technology Inc" 997 "Xenta Systems Srl" 996 "Eniquest Pty Ltd" 995 "Circuitlink Pty Ltd." 994 "Morris Industries Ltd." 993 "Alelion Energy Systems AB" 992 "MarineIOT LLC" 991 "Deutronic Elektronik GmbH" 990 "SAMSUNG SDI Co., Ltd." 989 "Flux-Geräte GmbH" 988 "Voith Turbo" 987 "Baltic Car Equipment" 986 "AAMP Global" 985 "NLR, LLC" 984 "E-T-A Elektrotechnische Apparate GmbH" 983 "Dezwaef NV" 982 "Briggs & Stratton Corporation" 981 "Kobelt Manufacturing Co. Ltd" 980 "Gussi Italia S.R.L." 979 "McHale" 978 "Canfield Connector" 977 "Copeland LP (formerly Emerson Electric Co.)" 976 "Derive Systems, Inc." 975 "Siemens AG" 974 "Pico Technology Limited" 973 "Zasso GmbH" 972 "Axion AG" 971 "B+B Smartworx" 970 "Jaboni Power Products, LLC" 969 "Blue Sea Systems" 968 "Cox Powertrain Limited" 967 "Moteck Electric Corp." 966 "VisibleFarm" 965 "Ro-Sys Software" 964 "AgroVIR Kft" 963 "Thomason Jones Company, LLC" 962 "Timbolier Industries, Inc." 961 "POK SAS" 960 "Vemcon GmbH" 959 "Cascade Corporation" 958 "NHK MEC Corporation" 957 "Sierra Wireless Inc" 956 "Piher Sensors & Controls S.A." 955 "Hottinger Baldwin (Suzhou) Electronic Measurement Technology Co., Ltd." 954 "Setec Pty Ltd" 953 "Curtiss-Wright" 952 "Tan Delta Systems Ltd" 951 "Exor International S.p.A." 950 "RE:Lab s.r.l." 949 "ŠKODA ELECTRIC a.s." 948 "Donix" 947 "Gerd Bär GmbH" 946 "Hydac Tecnologia Ltda" 945 "Equalizer AG" 944 "ZONTISA Marine SL" 943 "FISCHER AG Präzisionspindeln" 942 "Vogelsang GmbH & Co. KG" 941 "Navya" 940 "Dometal Oy" 939 "Warn Industries, Inc." 938 "LEVEL Systems" 937 "Precision Circuits Inc" 936 "Hi-tech Millennium" 935 "Meels GmbH & Co. KG" 934 "Farmobile, Inc." 933 "Delta Mobile Systems, Inc." 932 "Discover Battery" 931 "Enertec Marine Ltd" 930 "Ecotronix Corp." 929 "Jl Marine Systems, Inc." 928 "EAO Automotive GmbH & Co. KG" 927 "Saicon" 926 "Buhler Industries Inc." 925 "GW Lisk Company" 924 "PAS Peschak Autonome Systeme GmbH" 923 "ELTEK S.p.A." 922 "Terberg Benschop B.V." 921 "ROPA Fahrzeug- und Maschinenbau GmbH" 920 "MTD Consumer Group Inc." 919 "Furrion LLC" 918 "AMW Machine Control, Inc" 917 "Sentinel d.o.o." 916 "Hans Turck GmbH & Co. KG (formerly Turck Inc.)" 915 "Dosificacion y sistemas electronicos S.L. (DSE)" 914 "ZETOR TRACTORS a.s." 913 "Toyota Motor Corporation" 912 "Steyr Motors GmbH" 911 "Nautic-On" 910 "Hermann Paus Maschinenfabrik GmbH" 909 "Marines Co., Ltd." 908 "Chonbuk National University Department of Electronics" 907 "strautmann" 906 "MOBA AG" 905 "ASA Electronics" 904 "Equipment Safety Systems Pty. Ltd. (EQSS)" 903 "InMotion" 902 "Bucher Hydraulics" 901 "Zivan Srl" 900 "OSB connagtive GmbH (formerly OSB AG)" 899 "Lippert Components, Inc" 898 "Josef Kotte Landtechnik GmbH & Co. KG" 897 "Dot Technology Corp." 896 "NextFour Solutions Ltd" 895 "Peloton Technology" 894 "Rhodan Marine Systems of Florida LLC (Duplicate entry; use MFR ID 1012)" 893 "KlinkTechnics Ltd." 892 "Mectronx Corp" 891 "CarrierWeb" 890 "L3 Technologies, Inc." 889 "SANY America Inc" 888 "Carma Systems Inc" 887 "Turntide Transport Limited (formerly Hyperdrive Innovation Limited)" 886 "Hitachi Zosen Corporation" 885 "SICK AG (formerly SICK Stegmann GmbH)" 884 "Sure Grip Controls Inc." 883 "Swift Navigation, Inc." 882 "BHTronik GmbH & Co. KG" 881 "Sovema" 880 "Revision Military" 879 "PG Trionic, Inc." 878 "FOTON" 877 "SICK ATech GmbH" 876 "SUCO Robert Scheuffele GmbH & Co. KG" 875 "Salvarani S.r.l." 874 "MTA S.p.A." 873 "Garnet Instruments Ltd." 872 "Kählig Antriebstechnik GmbH" 871 "Agri-Fab (formerly Superior Tech Inc)" 870 "Textron Fleet Management" 869 "Intercomp" 868 "Data Panel Corp" 867 "Skeleton Technologies" 866 "Netradyne, Inc." 865 "MyEasyFarm" 864 "Streamline Transportation Technologies Inc." 863 "SMAG" 862 "Prospec Electronics" 861 "Adel System S.r.l." 860 "Michelin" 859 "Valor" 858 "Littelfuse" 857 "Zoomlion Heavy Industry NA, Inc" 856 "FarmFacts GmbH" 855 "Toshiba Infrastructure Systems & Solutions Corporation" 854 "GEMAC Chemnitz GmbH" 853 "Teledyne RESON B.V." 852 "Velvac Inc" 851 "Novotechnik Messwertaufnehmer OHG" 850 "Geoprospectors GmbH" 849 "MTS Maschinentechnik Schrode AG" 848 "ningupex" 847 "Oceanvolt" 846 "L3 Magnet-Motor" 845 "GMB Güstrower Maschinenbau GmbH" 844 "FELL AS" 843 "Hendrickson Truck Commercial Vehicle Systems" 842 "DigiDevice Srl" 841 "Agra-GPS" 840 "E.S.T.E. Srl" 839 "Indexator Rotator Systems AB" 838 "Teamsurv Ltd" 837 "Famic Technologies Inc." 836 "Signature4" 835 "PetTrack Ltd." 834 "Pioneer Microsystems, Inc." 833 "Electrum Automation AB" 832 "Heizomat Gerätebau-Energiesysteme GmbH" 831 "DOK-ING Ltd." 830 "Ultra Motion LLC" 829 "Drov Technologies, Inc." 828 "AgriBrink Inc." 827 "INmatix Technology Group Ltd" 826 "Lewmar Marine Inc" 825 "BPW Hungária" 824 "Undheim Systems AS" 823 "ACEINNA, Inc (formerly MEMSIC, Inc)" 822 "Bren-Tronics, Inc." 821 "Thorsen Teknik A/S" 820 "DIaLOGIKa Gesellschaft fuer angewandte Informatik mbH" 819 "Preco Electronics" 818 "HGNSS" 817 "TE Connectivity Sensor Solutions" 816 "UniStrong" 815 "FLIR Systems, Inc." 814 "Kronotech Srl (formerly Soltec Soluzioni Tecnologiche Srl)" 813 "Thales Suisse SA" 812 "Torch Technologies" 811 "Blue Water Desalination" 810 "Dutch Power Company" 809 "HMS Industrial Networks AB" 808 "RIMEX Supply Ltd." 807 "Schneider-Electric" 806 "Charge Automotive Ltd" 805 "Gundersen & Løken AS" 804 "ASA Electronics" 803 "Gill Sensors & Controls Limited" 802 "SPBI (Bj Technologie)" 801 "LOR Manufacturing Company Inc." 800 "Delta-Q Technologies" 799 "Stillwater Designs and Audio, Inc. - KICKER" 798 "Lumishore Ltd" 797 "Tides Marine" 796 "Canadian Automotive Industries Ltd" 795 "Broyda Enterprises Pty Ltd" 794 "Shihlin Electric & Engineering Corporation" 793 "James Fisher Prolec" 644 "KUS USA" 643 "Bogballe A/S" 642 "Moog / Aspen Motion Technologies" 641 "Diverse Yacht Services" 640 "Power Solutions International" 639 "Startec s.r.l." 638 "KVH Industries, Inc." 637 "Bavaria Yachtbau GmbH" 636 "Divelbiss Corporation" 635 "Argo Tractors S.p.A." 634 "Rocky Research" 633 "TORC Robotics" 632 "Pepperl+Fuchs GmbH" 631 "Reltima" 630 "SmartDrive Systems Inc." 629 "Agri Info Design, Ltd." 628 "Falck Schmidt Defence Systems" 627 "Radio Ocean" 626 "AVL DiTEST GmbH" 625 "Global MRV Inc." 624 "Blackbox Machine Control Pty Ltd" 623 "Xirgo Technologies" 622 "Floyd Bell Inc" 621 "Hagie Manufacturing Company" 620 "BorgWarner Inc. (formerly Sevcon Ltd.)" 619 "Right Weigh Load Scales" 618 "Evrard SA" 617 "Zero Emission Vehicles" 616 "SMART-TEC s.r.o." 615 "Networkfleet, Verizon Telematics" 614 "ARLT Technologies GmbH" 613 "HKS Co., Ltd." 612 "Samwon IT" 611 "Esterline" 610 "Trail Tech" 609 "Walvoil S.p.A." 608 "Gale Banks Engineering" 607 "Knappco/Civacon" 606 "Intellian Technologies" 605 "Aventics GmbH" 604 "Rototilt Group AB (formerly Indexator Rototilt Systems AB)" 603 "Kereval" 602 "Nomad Digital Ltd." 601 "Navitas Systems" 600 "Aquatic AV" 599 "Spudnik Equipment Co, LLC" 598 "ABB Turbo Systems Ltd" 597 "Hydac Filter Systems GmbH" 596 "Brunelco Electronic Innovators B.V." 595 "CustomWare" 594 "Kongsberg Automotive" 593 "Sensata Technologies" 792 "Kostal Mexicana" 791 "AUTEC" 790 "VACALL" 789 "GRADALL" 788 "MoTeC Pty Ltd" 787 "Abertax Technologies Limited" 786 "Johnson Matthey Battery Systems" 785 "Fischer Panda GmbH" 784 "CM Automotive Systems, Inc." 783 "Loup Electronics Inc." 782 "AVR nv" 781 "Poly-Planar LLC" 780 "Turntide Transport Limited (formerly AVID Technology Ltd)" 779 "RLC Electronic Systems" 778 "Seakeeper Inc." 777 "Ocean Signal Ltd" 776 "HMI Systems LLC" 775 "ZIEHL-ABEGG Automotive GmbH" 774 "Taisho Corporation" 773 "Clarion Corporation of America" 772 "Blink Marine" 771 "Shaw Development, LLC" 770 "MONOSEM" 769 "Trombetta" 768 "Flores Automation, LLC" 767 "Alliance Wireless Technologies Inc." 766 "Epec Oy" 765 "GIGAVAC" 764 "Bednar FMT s.r.o." 763 "AT-Systems BVBA" 762 "ROJ s.r.l." 761 "MITA OLEODINAMICA S.p.A." 760 "Bernecker + Rainer Industrie Elektronik GmbH" 759 "Hydro-Gear" 758 "Banner Engineering Corp." 757 "IMPCO Technologies" 756 "Maschio Gaspardo S.P.A." 755 "Firefly Integrations" 754 "Parker Hannifin Corp., Automation Group" 753 "AIROD Technologies" 752 "Deep Sea Electronics Plc" 751 "Pacific Track" 750 "Joskin SA" 749 "Chart Inc." 748 "IFRA SRL - ISOTTA" 747 "Agratronix" 746 "SurePoint Ag Systems (formerly SureFire Ag Systems, Inc.)" 745 "Cidra Corporate Services Inc." 744 "Woosung Engineering Co., Ltd." 743 "Daemyung Elevator Co., Ltd." 742 "EROAD" 741 "Littelfuse, Inc (formerly Carling Technologies)" 740 "e-Traction" 739 "LXNAV d.o.o." 738 "Blue Ink Technologies" 737 "Balluff GmbH" 736 "Terex Aerial Work Platforms - Genie" 735 "AEM Performance Electronics" 734 "REAPsystems" 733 "Geotab Inc. (formerly Intendia S.L.)" 732 "Gefran S.p.A." 731 "Modine Manufacturing Company" 730 "BERTHOUD AGRICOLE" 729 "Liebherr" 728 "Streumaster (formerly Streumaster / Panien)" 727 "Dhoot Transmission Pvt Ltd." 726 "MIDORI PRECISIONS" 725 "Hitachi Construction Machinery Co., Ltd." 724 "Electronic Applications, Inc." 723 "Jabil Inc." 722 "Contelec AG" 721 "Hypro" 720 "WITZ Corporation" 719 "Cojali S. L." 718 "Micronet Inc" 717 "Yacht Devices Ltd" 716 "Eaton Control & Power Conversion Division (CPCD)" 715 "Autonnic Research Ltd" 714 "Kobashi Kogyo Co., Ltd." 713 "US Hybrid Corporation" 712 "LOR Manufacturing Company Inc." 711 "DAS Co., LTD" 710 "Greentronics Ltd." 709 "Marquardt GmbH" 708 "Lars Thrane A/S" 707 "Rochester Gauges Inc" 706 "Shanghai Diesel Engine Corporation Limited" 705 "SVAB Hydraulik AB" 704 "JL Audio, Inc." 703 "Hydro Tab Marine Engineering" 702 "Weichai Power Co., Ltd." 701 "BigRoad Inc." 700 "K-Tec Earthmovers Inc." 699 "Harman International (formerly Harman International Industries)" 698 "Scorpion Technologies Ltd." 697 "Ålö AB" 696 "DRS Network & Imaging Systems, LLC (DRS Technologies)" 695 "Weldon Technologies" 694 "GasTOPS Ltd." 693 "Agility Fuel Solutions (formerly Agility Fuel Systems)" 692 "Tanhay Corporation" 691 "Digitroll Agricultural Electronics" 690 "LINAK A/S" 689 "Aarcomm Systems Inc" 688 "Rockford Corp" 687 "Flight Systems, Inc." 686 "Taigene Electric Machinery Corp." 685 "ANEDO (formerly ANEDO Ltd.)" 684 "KEB" 683 "Fosen Elektro" 682 "Eckelmann AG" 681 "BEDIA Motorentechnik GmbH & Co. KG" 680 "AMVAC Chemical Corporation" 679 "OXE Marine AB (formerly Cimco Marine AB)" 678 "Motive Technologies, Inc. (formerly KeepTruckin, Inc.)" 677 "DSA Daten- und Systemtechnik GmbH" 676 "Danfoss IXA A/S" 675 "Kawasaki Motors, Ltd. (formerly Kawasaki Motors Corp., USA)" 674 "Yara International ASA" 673 "Caruelle Nicolas" 672 "OPTIMA Concept" 671 "Innovative Controls Inc." 670 "STEMCO LP" 669 "Quantum Fuel Systems Technologies Worldwide, Inc" 668 "MacDon Industries Ltd." 667 "Bartec" 666 "Schaeffler Technologies AG & Co., KG" 665 "Gebr. Bode GmbH & Co. KG" 664 "Level Developments Ltd" 663 "Delta Systems, Inc" 662 "Kissling Elektrotechnik GmbH" 661 "SPAL Automotive S.r.l." 660 "Auto-Gaz Centrum" 659 "Data Panel Corp." 658 "Shenzhen Jiuzhou Himunication Technology Co., Ltd" 657 "Terzo Power Systems" 656 "PRO SOLUS do Brasil" 655 "Genge & Thoma AG" 654 "Kohler Power Systems, Detroit Engine Development Center (DEDC)" 653 "AEV, spol. s r. o." 652 "MicroControl GmbH & Co. KG" 651 "Takakita Co, Ltd." 650 "Seiko Epson Corp." 649 "Control-Q B.V." 648 "OJSC Ekran" 647 "Siloking" 646 "Veenhuis Machines B.V." 645 "esd electronic system design gmbh" 592 "tecsis GmbH" 591 "United States Coast Guard" 590 "ARGO-HYTOS GMBH" 589 "MICO, Inc." 588 "Vignal Systems" 587 "JCA Electronics" 586 "Suzuki Motor Corp" 585 "Industrial Electronic Controls" 584 "CarMedialab GmbH" 583 "Yachtcontrol" 582 "Innovative Software Engineering" 581 "Väderstad AB (formerly Väderstad - Verken AB)" 580 "San Jose Technology, Inc." 579 "KVH Industries, Inc." 578 "advanSea" 577 "Denchi Power Ltd  (formerly ABSL Power Solutions Limited)" 576 "Vectia" 575 "Lytx" 574 "Vishay Precision Group" 573 "Orolia Ltd" 572 "Fasse Valves" 571 "Marinecraft Co., Ltd." 570 "frenzel + berg electronic GmbH & Co. KG" 569 "LORD MicroStrain Sensing Systems" 568 "Makersan Ltd. Co." 567 "Lithiumstart LLC" 566 "Geode Technology, Inc." 565 "Micro-Trak Systems, Inc." 564 "Auto Power Electronic" 563 "LOHR Sistemas Eletronicos LTDA" 562 "Bombardier Transportation GmbH" 561 "b-plus GmbH" 560 "Iowa State University, Agricultural and Biosystems Engineering" 559 "Four Peaks Navigation" 558 "Davis Instruments Corp." 557 "Rockson Automation GmbH" 556 "HD Hyundai Infracore Norway (formerly Doosan Infracore Norway)" 555 "Sasaki Corporation" 554 "iris-GmbH infrared & intelligent sensors" 553 "KIB Electronics" 552 "Matsuyama Plow Mfg Co, Ltd" 551 "Wexler CSD Ltd." 550 "SUN-A Corporation" 549 "ROAD Deutschland GmbH" 548 "TM4 Inc." 547 "Thomson Linear LLC" 546 "Maruyama Mfg Co, Inc." 545 "GS Global Resources (formerly GS Hydraulics)" 544 "Au Group Electronics" 543 "BAUER Maschinen GmbH" 542 "Dinamica Generale s.p.a." 541 "Total Fire Systems, Inc." 540 "Dinex A/S" 539 "Mobileview" 538 "Crop Ventures, Inc." 537 "Schrader Electronics Ltd." 536 "SSI Technologies" 535 "MOTORPAL, a.s." 534 "Webasto Thermo & Comfort SE" 533 "Doran Manufacturing, LLC" 532 "Onwa Marine Electronics Co Ltd." 531 "Genge & Thoma AG" 530 "NMEA" 529 "National Instruments Korea" 528 "Hoganas AB, Electric Drive Systems" 527 "GKN Walterscheid GmbH" 526 "LOFA Industries, Inc" 525 "Rust Sales INC" 524 "Vomax Instrumentation Pty. Ltd." 523 "Reggio Emilia Innovazione" 522 "Nebraska Tractor Test Laboratory" 521 "Clever Devices Ltd." 520 "Trapeze" 519 "Peeters Landbouwmachines b.v." 518 "Transas USA Inc." 517 "Noland Engineering" 516 "AVAT Automation GmbH" 515 "GINAF Trucks Nederland B.V." 514 "DISTek Integration, Inc." 513 "Precision Technology" 512 "Inpower LLC" 511 "SKY Agriculture (formerly Burel Production, formerly Sulky)" 510 "Marinesoft Co. Ltd" 509 "MOTORTECH GmbH" 508 "Transtech Innovations" 507 "ISOBUS Test Center" 506 "IHI STAR Machinery Corporation" 505 "Yetter Farm Equipment" 504 "Vesper Marine" 503 "Naviop S.R.L." 502 "Attwood Corporation" 501 "Agrotronix S.A." 500 "Oxbo International Corporation" 499 "LCJ Capteurs" 498 "Innovative Design Solutions, Inc." 497 "SENTRON Sistemas Embarcados" 496 "W. Gessmann GmbH" 495 "HOLMER Maschinenbau GmbH" 494 "Synerject" 493 "Watcheye" 492 "Inergy Automotive Systems" 491 "Penny and Giles Ltd" 490 "QuikQ" 489 "Appareo Systems, LLC" 488 "The Charles Machine Works, Inc." 487 "DSE Test Solutions A/S" 486 "Westport Innovations Inc." 485 "MATT automotive" 484 "Headsight Inc." 483 "Valeo" 482 "Tricon Electronics" 481 "Chetco Digital Instruments" 480 "EnerDel, Inc." 479 "Vapor Bus International" 478 "OceanSat B.V." 477 "OilQuick AB" 476 "Hummingbird Marine Electronics" 475 "GME" 474 "Persen Technologies Inc." 473 "Boss Industries, Inc." 472 "Tenneco Inc." 471 "Sea Cross Marine AB" 470 "SI-TEX Marine Electronics" 469 "RA Consulting GmbH" 468 "Tyco Fire Protection Products" 467 "Lely Industries N.V." 466 "Veethree Electronics and Marine LLC" 465 "Ashcroft Inc" 464 "Leach International Corporation" 463 "PROBOTIQ" 462 "IHI Shibaura Machinery Corporation" 461 "HAWE Hydraulik SE" 460 "San Giorgio S.E.I.N." 459 "Alltek Marine Electronics Corp" 458 "Control Solutions, Inc." 457 "RUSELPROM-ElectricDrive Ltd" 456 "General Kinetics" 455 "ADZ NAGANO GmbH" 454 "NGK Spark Plug Co. Ltd" 453 "Cooper Bussmann" 452 "WIKA Alexander Wiegand SE & Co. KG" 451 "Parker Hannifin Corp" 450 "Dycor Technologies Ltd." 449 "Polaris Industries Inc" 448 "Stanadyne Corporation, Electronics Systems" 447 "Great Plains Mfg." 446 "CertTech, L.L.C." 445 "KAT MECHATRONIC, Electronic Product Division" 444 "ITT Power Solutions" 443 "SignalQuest, Inc." 442 "Horsch Maschinen GmbH" 441 "PTG Reifendruckregelsysteme GmbH" 440 "Cummins Power Generation" 438 "Comar Systems Ltd" 437 "Digital Yacht Limited" 436 "Kinze Manufacturing" 435 "Zunhammer GmbH" 434 "Stored Energy Systems" 433 "Rowe Electronics" 432 "S&A Systems, Inc." 431 "Tohatsu Corporation" 430 "Auteq Telematica S.A." 429 "Rota Engineering Ltd." 425 "Methode Electronics Inc, MDI" 424 "Odyne LLC" 423 "BSM Wireless, Inc." 422 "True Heading AB" 421 "Vertex Standard Co, Ltd" 420 "Vermeer Corporation, ACS Group" 419 "Fusion Electronics Ltd" 418 "Intellistick Inc" 417 "KZValve" 416 "Kubota Corporation" 415 "Valid Manufacturing Ltd." 414 "Cattron Group International" 413 "Datapross Nijbroek bv" 412 "WebTech Wireless Inc." 411 "Hy-Drive Technologies Ltd." 410 "COBO S.p.A. Divisione 3B6" 409 "Transfluid S.r.L." 408 "Corvus Energy Ltd." 407 "Comtech Mobile Datacom" 406 "Vecima Networks Inc." 405 "Wema System AS" 404 "Com Nav Marine Ltd" 403 "Trackwell ADS, Inc." 402 "Simma Software, Inc." 401 "Torqeedo GmbH" 400 "Livorsi Marine" 399 "ISEKI & Co., Ltd." 398 "Hilite International" 397 "Sanyo-kiki Co Ltd." 396 "Beyond Measure" 395 "GENTEC S.R.L." 394 "Capi 2 Nederland B.V." 393 "Harvest Tec, Inc" 392 "Tianyuan Technology Co Ltd." 391 "Electronic Design for Industry, Inc" 390 "Partech Inc." 389 "Benchmark Electronics, Minnesota Division" 388 "Innomatix, LLC" 387 "Orscheln Products, LLC" 386 "JLG Automation BVBA" 385 "Johnson Outdoor Marine Electronics" 384 "Camano Light" 383 "MCL Industries" 382 "National Agriculture and Food Research Organization" 381 "B & G" 380 "Suntech International Ltd." 379 "Yamabiko Corporation" 378 "Glendinning Marine Products" 377 "ifm electronic gmbh" 376 "Quake Global" 375 "Williams Controls Inc." 374 "Northern Lights, Inc." 373 "Electronic Design Inc." 372 "Delphi" 371 "Heinzmann GmbH & Co. KG" 370 "Rolls-Royce Marine AS" 369 "Power Torque Engineering Ltd" 368 "HANSENHOF_electronic" 367 "Fliegl Agrartechnik" 366 "Viewnyx Corp." 365 "Digi-Star, LLC" 364 "OEM Controls Inc." 363 "BEI Duncan" 362 "Poettinger Landtechnik GmbH (formerly Alois Poettinger Maschinenfabrik GmbH)" 361 "InMach" 360 "HJS Emission Technology GmbH & Co KG   (formerly HJS Fahrzeugtechnik GmbH & Co KG)" 359 "Ludwig Bergmann GmbH" 358 "Victron Energy B.V." 357 "Hardi International A/S" 356 "Fischer Panda Generators, Inc" 355 "Mastervolt International B.V." 354 "Junkkari OY" 353 "Hegemon Electronics, Inc." 352 "SAME DEUTZ-FAHR GROUP S.p.A." 351 "Thrane & Thrane" 350 "Noris Marine Systems GmbH & Co KG" 349 "Suonentieto" 348 "Amazonen Werke H. Dreyer" 347 "Honeywell" 346 "Control Solutions" 345 "Korean Maritime University" 344 "Parvus Corporation" 343 "Baumer Group" 342 "THOMAS MAGNETE GmbH" 341 "Boning GmbH & Co" 340 "Continental AG" 339 "Competence Center ISOBUS e.V." 338 "GRAF-SYTECO" 184 "EIA Electronics" 183 "KDS Controls, Inc" 182 "Vehicle Systems Engineering B.V." 181 "Coretronics, Inc." 180 "Smart Power Systems" 179 "TeeJet Technologies Springfield (formerly Midwest Technologies Illinois, LLC)" 178 "Continental Automotive GmbH (formerly Siemens VDO Automotive AG)" 177 "Diagnostic Systems Associates" 176 "Moritz Aerospace" 175 "Veris Technologies, Inc." 174 "AB Volvo Penta" 173 "Ryeso, Inc." 172 "Yanmar Co., Ltd. (formerly Yanmar Marine USA)" 171 "Topcon Electronics GmbH & Co. KG (formerly Wachendorff Elektronik GmbH & Co. KG)" 170 "Computronics Corporation Ltd." 169 "Marlin Technologies Inc." 168 "Xantrex" 167 "JLG Industries Inc" 166 "John Deere Electronic Solutions (formerly Phoenix International)" 165 "CPAC Systems AB" 164 "MTU Friedrichshafen GmbH (formerly DaimlerChrysler Off-Highway)" 163 "BRP Inc." 162 "Axiomatic Technologies" 161 "Offshore Systems (UK) Ltd" 160 "Nido" 159 "NTech Industries Inc" 158 "Firestone Industrial Products Company" 157 "ISSPRO Inc." 156 "ITT Industries - Cannon" 155 "Vetronix Corporation" 154 "Westerbeke Corporation" 153 "Woodward, Industrial Controls Division" 152 "elobau GmbH & Co. KG" 151 "Raven Industries, Inc." 150 "Fleetguard" 149 "Holset" 148 "Blue Water Data, Inc." 147 "Nautibus electronic GmbH" 146 "Maxima Technologies" 145 "MurCal Controls" 144 "Mercury Marine" 143 "W. Gmeiner GmbH & Co." 142 "TRW Automotive (Commercial Steering Systems)" 141 "Thales Navigation Ltd." 140 "Lowrance Electronics, Inc." 97 "Ag Leader Technology, Inc." 96 "Mech@tronic IT GmbH" 95 "Pacific Insight Electronics Corp." 94 "CNH Industrial N.V. (formerly CNH Global N.V.)" 93 "Perkins Engines Company Ltd." 92 "Ag-Chem Equipment Co., Inc." 91 "BSG Bodensee Steuergeraete GmbH" 90 "Knorr-Bremse SfN GmbH" 89 "Kverneland Group, Electronics Division" 88 "Hemisphere GPS Inc (formerly Satloc Precision GPS)" 87 "J.C. Bamford Excavators Ltd (JCB)" 86 "C. E. Niehoff & Company" 85 "Kohler Co" 84 "New Holland UK Limited" 83 "Bendix VORAD Technologies (formerly Eaton VORAD Technologies)" 82 "Bobcat/Ingersoll-Rand (formerly Melroe/Ingersoll-Rand)" 81 "Fire Research Corp." 80 "Twin Disc, Inc." 79 "Daimler Benz AG - Engine Division (PBM)" 78 "Frank W. Murphy Manufacturing, Inc" 77 "Deere Power Systems Group" 76 "unused (formerly Deere & Co, Construction Division)" 75 "Deere & Co, Agricultural Division" 74 "Eaton Axle-Brake Division" 73 "LeTourneau, Inc." 72 "Sisu Corporation" 71 "Vansco Electronics Ltd." 70 "Flex-coil Limited" 69 "Trimble Navigation" 68 "Scania" 67 "John Deere Coffeyville Works (formerly Funk Manufacturing Company)" 66 "John Deere Construction Equipment Division" 65 "MAN Nutzfahrzeuge AG" 64 "Unused (formerly SpectraPrecision Laserplane, then SpectraPhysics)" 63 "ZF Industries Inc." 62 "Wabco" 61 "Volvo Truck Corp." 60 "Volvo Trucks North America Inc." 59 "VES Inc." 58 "SPX Corporation, OTC Div" 57 "Danfoss  (formerly Sauer Sundstrand Co, then Sauer-Danfoss Co)" 337 "Carraro S.p.A." 336 "APE s.r.o." 335 "Evo Electric Ltd" 334 "Takata-Petri AG" 333 "Link Manufacturing, Ltd. (formerly Hadley Products Corporation)" 332 "HWH Corporation" 331 "Horton, Inc." 330 "Kidde Aerospace and Defense" 329 "Deif A/S" 328 "Qwerty Electronik AB" 327 "Sonceboz SA" 326 "Akron Brass Company" 325 "ASM Automation Sensorik Messtechnik GmbH" 324 "Snap-on Diagnostics" 323 "Mobileye Vision Technologies Ltd." 322 "MICHENKA s.r.o." 321 "Ultra Electronics, Electrics" 320 "Miedema Landbouwwerktuigenfabriek B.V." 319 "Cadec Global" 318 "SAT Plan" 317 "Navtronics Bvba" 316 "ITT Flow Control" 315 "Icom Incorporated" 314 "CSM GmbH" 313 "Ilmor Engineering, Inc." 312 "Lectronix, Inc." 311 "Patrick Power Products" 310 "TECNORD srl" 309 "Krauss-Maffei Wegmann GmbH & Co. KG" 308 "Cyntrx" 307 "MAS Technologies" 306 "Sleipner Motor AB" 305 "NovAtel Inc" 304 "EmpirBus AB" 303 "CTS Corporation" 302 "Nissin Kogyo Co., LTD" 301 "Parker Hannifin (UK) Ltd FDE group" 300 "Systron Donner Automotive" 299 "Rauch" 298 "Holley Performance" 297 "Zonar Systems Inc" 296 "micro dynamics GmbH" 295 "BEP Marine" 294 "Grayhill Inc." 293 "Spyder Controls Corp." 292 "IKUSI - Angel Iglesias S.A." 291 "Groeneveld Transport Efficiency BV" 290 "Kuebler GmbH" 289 "Watlow" 288 "Mitsubishi FUSO Truck & Bus Corp." 287 "NTech Industries, Inc" 286 "Coelmo srl" 285 "Sea Recovery Corp" 284 "Mobile Tech Chile" 283 "CWF Hamilton & Co Ltd" 282 "Medallion Instrumentation Systems" 281 "Precision Governors LLC" 280 "Leica Geosystems Pty Ltd" 279 "Geometris LP" 278 "Takata Electronics" 277 "LHP Telematics" 276 "Aqua-Hot Heating Systems" 275 "Navico Egersund AS" 274 "LTW Technology Co., LTD" 273 "Active Research Limited" 272 "Gross Mechanical Laboratories, Inc" 271 "Cole Hersee" 270 "Tennant" 269 "Saft America Inc.,  Space & Defense Division" 268 "Accurate Technologies" 267 "Red Lion Controls, Inc" 266 "International Thermal Research Ltd" 265 "MTS Sensor Technologie GmbH" 264 "Autolync" 263 "IMMI" 262 "HydraForce, Inc" 261 "Red Dot Corporation" 260 "Reichhardt GmbH Steuerungstechnik" 259 "Bucher Automation AG (formerly Jetter AG)" 258 "ARAG" 257 "Honda Motor Co., Ltd" 256 "Tyco Electronics AMP" 255 "MEAS France" 254 "GE Sensing" 253 "Mobile Control Systems" 252 "Sensor-Technik Wiedemann GmbH" 251 "German Agricultural Society, Test Center (DLG)" 250 "Kuhn Group" 249 "Schaltbau GmbH" 248 "Cooper Standard Automotive Active Systems Group" 247 "ePULSE" 246 "Class 1, Inc" 245 "Capstan Ag Systems, Inc." 244 "Techno-Matic" 243 "eRide, Inc." 242 "Kokusandenki Co. Ltd" 241 "Schneider Automation SAS" 240 "Vanair Manufacturing" 239 "May & Scofield Ltd" 238 "ZF Friedrichshafen AG" 237 "Agtron Enterprises Inc" 236 "NORAC Systems International Inc" 235 "SailorMade Marine Telemetry - Tetra Technology Ltd." 234 "Mondial electronic GmbH" 233 "Yacht Monitoring Solutions Inc." 232 "TSD Integrated Controls" 231 "Topcon Positioning Systems, Inc." 230 "Saucon Technologies" 229 "Garmin International Inc." 228 "Unused (formerly ZF Marine Electronics)" 227 "Lykketronic A/S" 226 "Monaco Coach Corporation" 225 "SKF" 224 "EMMI Network, S.L." 223 "Vaueo Retarder Co., Ltd." 222 "Generac Power Systems, Inc." 221 "SiE" 220 "Beede Electrical Instrument Company, Inc" 219 "Cat OEM Solutions" 218 "Gits Manufacturing Company" 217 "RM Michaelides Software & Elektronik GmbH" 216 "Paneltronics Inc." 215 "Aetna Engineering/Fireboy-Xintex" 214 "MC elettronica Srl" 213 "CNH Belgium N.V." 212 "Sure Power Industries, Inc" 211 "DNA Group" 210 "Iteris, Inc." 209 "Bell Equip. Co. SA (PTY) LTD" 208 "Drew Technologies, Inc" 207 "Otto Engineering" 206 "port GmbH" 205 "SmarTire Systems Inc" 204 "The Morey Corporation" 203 "MILtronik GmbH" 202 "Curtis Instruments, Inc" 201 "Disenos y Tecnologia S.A." 200 "MGM Brakes" 199 "ACTIA Group (formerly Actia Corp)" 198 "Mystic Valley Communications" 197 "Mechron Power Systems" 196 "LEMKEN GmbH & Co KG" 195 "General Engine Products" 194 "TriMark Corporation" 193 "Jeppesen Marine" 192 "Floscan" 191 "XRS Corporation (formerly XATA Corporation)" 190 "Hella KGaA Hueck & Co" 189 "QUALCOMM" 188 "EMP Corp" 187 "Air-Weigh" 186 "Altronic, Inc" 185 "Beede Electrical Instrument Company" 139 "Caterpillar Trimble Control Technologies (CTCT), LLC" 138 "Georg Fritzmeier GmbH & Co. KG" 137 "Littelfuse, Inc (formerly Maretron)" 136 "Komatsu Ltd" 135 "Airmar Technology Corporation" 134 "Iris Technology Ltd" 133 "Bucher Schoerling GmbH" 132 "Mulag-Fahrzeugwerk" 131 "ITT Industries" 130 "Nido - Universal Machines B.V." 129 "OMNEX Control Systems Inc." 128 "Gerhard Duecker GmbH & Co. KG" 127 "Holland USA" 126 "Driver Tech" 125 "Nevada Automotive Test Center" 124 "Hydac Electronic" 123 "Basler Electric" 122 "FG Wilson (Engineering) Limited" 121 "HED (Hydro Electronic Devices, Inc.)" 120 "RDS Technology Ltd" 119 "IntegriNautics  " 118 "Intron GmbH" 117 "HUSCO International" 116 "BEELINE Technologies" 115 "NACCO Materials Handling Group, Inc." 114 "EControls, Inc." 113 "Stress-Tek, Inc." 112 "MECALAC" 111 "Bernard Krone Holding SE & Co. KG (formerly Maschinenfabrik Bernard Krone GmbH)" 110 "EPIQ Sensor-Nite" 109 "TeeJet Technologies Denmark (formerly LH Technologies ApS)" 108 "PTx Trimble (formerly WTK-Elecktronik GmbH, now a duplicate entry; use MFR ID 98)" 107 "Grimme Landmaschinen GmbH & Co. KG" 106 "BAE Systems Controls, Inc." 105 "Kiepe Elektrik GmbH & Co. KG" 104 "CLAAS KGaA mbH (formerly CLAAS Selbstfahrende Erntemaschinen GmbH)" 103 "CLAAS E-Systems GmbH (formerly CLAAS E-Systems KGaA mbH & Co. KG)" 102 "AGCO (formerly AGCO GmbH & Co.)" 101 "Sensoria" 100 "VDO Technik AG" 99 "International Transmissions Ltd (ITL)" 98 "PTx Trimble (formerly Mueller-Elektronik GmbH & Co)" 56 "SAIC" 55 "Ryder System Inc." 54 "Meritor Wabco" 53 "Continental Automotive Systems US, Inc. (formerly Rockwell Land Transportation)" 52 "Meritor Automotive, Inc. (formerly Rockwell Automotive)" 51 "Robert Bosch GmbH" 50 "Robert Bosch Corp" 49 "RE America Inc." 48 "Pollak Alphabet" 47 "Phillips Semiconductor" 46 "Noregon Systems, LLC  (formerly Noregon Systems, Inc)" 45 "PACCAR" 44 "Nippondenso Co. Ltd." 43 "International Truck and Engine Corporation - Vehicle Electronics (formerly Navistar Intl Trans Corp.)" 42 "International Truck and Engine Corporation - Engine Electronics  (formerly Navistar Intl Trans Co., Engine Electronics)" 41 "Motorola Inc." 40 "Motorola AIEG Inc." 39 "Microfirm Inc." 38 "Micro Processor Systems Inc." 37 "Mack Trucks Inc." 36 "Lucas Ind." 35 "Kenworth Truck Co." 34 "Kelsey Hayes Co." 33 "John Deere" 32 "Jacobs Vehicle Systems" 31 "J Pollak Corp" 30 "Isuzu Motors Ltd" 29 "Hino Motors Ltd." 28 "Grote Ind. Inc." 27 "GMC" 26 "General Motors Corp, Service Technology Grp" 25 "Daimler Trucks North America LLC (formerly Freightliner LLC)" 24 "Ford Motor Co., Vehicle Controls" 23 "Ford Motor Co., Heavy Truck" 22 "Ford Motor Co., Electronic Concepts & Systems" 21 "Echlin Inc., Midland Brake Inc." 20 "Eaton Ltd" 19 "Eaton Corp. Trucking Info Services" 18 "Eaton Corp, Transmission Div." 17 "Eaton Corp, Corp Res & Dev" 16 "Eaton Corp" 15 "DICKEY-john Corporation" 14 "Detroit Diesel Corporation" 13 "Delco Electronics" 12 "Deere & Company, Precision Farming" 11 "Dearborn Group Inc." 10 "Cummins Inc (formerly Cummins Engine Co)" 9 "Chrysler Corp." 8 "Caterpillar Inc." 7 "Case Corp." 6 "Berifors Electronics AB" 5 "AMP Inc." 4 "Ametek-Dixson" 3 "Ametek, US Gauge Division" 2 "Allison Transmission, Inc." 1 "Bendix Commercial Vehicle Systems LLC (formerly Allied Signal Inc.)" 0 "Reserved" ;
VAL_ 2565799678 VehicleSystem 0 "Non-specific System" 127 "Not Available" ;
VAL_ 2565799678 VehicleSystem5 127 "Not Available" 0 "Ind. Process Control Stationary" ;
VAL_ 2565799678 VehicleSystem4 125 "Entertainment" 120 "Display" 85 "External Environment" 75 "Sensor Communication Interface" 35 "Electrical Generation" 100 "Deck, Cargo and Fishing Equipment" 90 "Internal Environment" 80 "Instrumentation/General Systems (deprecate)" 70 "Communications" 60 "Navigation" 50 "Propulsion" 40 "Steering and Control Surfaces" 30 "Electrical Distribution" 25 "Inter/Intranetwork Device" 20 "Safety Systems" 10 "System Tools" 127 "Not Available" 0 "Non-specific System" ;
VAL_ 2565799678 VehicleSystem3 8 "Grader" 7 "Four Wheel Drive Loader" 6 "Forklift" 5 "Excavator" 4 "Crawler" 3 "Backhoe" 2 "Articulated Dump Truck" 1 "Skid Steer Loader" 127 "Not Available" 0 "Non-specific System" ;
VAL_ 2565799678 VehicleSystem2 25 "Slurry Applicators" 24 "Utility Vehicles" 23 "Mulchers" 22 "Timber Processing Machines" 21 "Timber loaders" 20 "Forwarders" 19 "Timber Harvesters" 17 "Sensor Systems" 16 "Skidder" 15 "Earth Work" 14 "Special Crops" 13 "Powered Auxiliary Device" 12 "Farm Yard Operations" 11 "Transport/Trailer" 10 "Irrigation" 9 "Forage" 8 "Root Harvesters" 7 "Harvesters" 6 "Sprayers" 5 "Fertilizers" 4 "Planters/Seeders" 3 "Secondary Tillage" 2 "Tillage" 1 "Tractor" 127 "Not Available" 0 "Non-specific System" ;
VAL_ 2565799678 VehicleSystem1 2 "Trailer" 1 "Tractor" 127 "Not Available" 0 "Non-specific System" ;
VAL_ 2565668606 RoleOfSender 3 "Sender role not specified" 2 "Reserved by SAE" 1 "Stop TP Connection where the current sender is the TP responder" 0 "Stop TP Connection where the current sender is the TP originator" ;
VAL_ 2565668606 ConnectionAbortReason 255 "Not available" 254 "Error indicator" 250 "Connection Abort reason is not listed" 9 "Total Message Size is greater than 1785 bytes" 8 "Duplicate sequence number (software cannot recover)" 7 "Bad sequence number (software cannot recover)" 6 "Unexpected data transfer packet" 5 "Maximum retransmit request limit reached" 4 "CTS messages received when data transfer is in progress." 3 "A timeout occurred and this is the connection abort to close the session." 2 "System resources were needed for another task so this connection managed session was terminated." 1 "Already in one or more connection managed sessions and cannot support another." ;
VAL_ 2565668606 PGNumber 255 "NotAvailable" ;
VAL_ 2565668606 ControlByte 255 "Abort" 32 "BAM" 19 "EoMA" 17 "CTS" 16 "RTS" ;
VAL_ 2563374846 UseTransferMode 3 "NA" 2 "Undefined" 1 "Yes" 0 "No" ;
VAL_ 2565406462 ControlByte 3 "CannotRespond" 2 "AccessDenied" 1 "NACK" 0 "ACK" ;
